AUTOSAR XML (schema 4-1-3)
standard types defined: boolean, sint8, uint16, uint32, uint8, boolean_CompuMethod, boolean_DataConstr, sint8_DataConstr, uint16_DataConstr, uint32_DataConstr, uint8_DataConstr, float32, Float
package /MICROSAR/Dem_swc/DataTypes
  5 x impl type:
    Dem_DebounceResetStatusType: compu {0=DEM_DEBOUNCE_STATUS_FREEZE, 1=DEM_DEBOUNCE_STATUS_RESET}, range raw 0..255, implementation-data-type=ImplementationDataTypes/uint8
    Dem_DTCFormatType: compu {0=DEM_DTC_FORMAT_OBD, 1=DEM_DTC_FORMAT_UDS, 2=DEM_DTC_FORMAT_J1939}, range raw 0..255, implementation-data-type=ImplementationDataTypes/uint8
    Dem_EventStatusType:
      compu {0=DEM_EVENT_STATUS_PASSED, 1=DEM_EVENT_STATUS_FAILED, 2=DEM_EVENT_STATUS_PREPASSED, 3=DEM_EVENT_STATUS_PREFAILED, 4=DEM_EVENT_STATUS_FDC_THRESHOLD_REACHED, 5=DEM_EVENT_STATUS_PASSED_CONDITIONS_NOT_FULFILLED, 6=DEM_EVENT_STATUS_FAILED_CONDITIONS_NOT_FULFILLED, 7=DEM_EVENT_STATUS_PREPASSED_CONDITIONS_NOT_FULFILLED, 8=DEM_EVENT_STATUS_PREFAILED_CONDITIONS_NOT_FULFILLED}
      range raw 0..255
      implementation-data-type=ImplementationDataTypes/uint8
    Dem_MaxDataValueType: category=ARRAY, sw-calibration-access=READ-ONLY
      element Dem_MaxDataValueTypeElement: array-size=4, array-size-semantics=FIXED-SIZE, implementation-data-type=ImplementationDataTypes/uint8
    Dem_UdsStatusByteType:
      compu {mask 1: 1=DEM_UDS_STATUS_TF (bit 0: TestFailed), mask 2: 2=DEM_UDS_STATUS_TFTOC (bit 1: TestFailedThisOperationCycle), mask 4: 4=DEM_UDS_STATUS_PDTC (bit 2: PendingDTC), mask 8: 8=DEM_UDS_STATUS_CDTC (bit 3: ConfirmedDTC), mask 16: 16=DEM_UDS_STATUS_TNCSLC (bit 4: TestNotCompletedSinceLastClear), mask 32: 32=DEM_UDS_STATUS_TFSLC (bit 5: TestFailedSinceLastClear), mask 64: 64=DEM_UDS_STATUS_TNCTOC (bit 6: TestNotCompletedThisOperationCycle), mask 128: 128=DEM_UDS_STATUS_WIR (bit 7: WarningIndicatorRequested)}
      range raw 0..255
      implementation-data-type=ImplementationDataTypes/uint8
package /MICROSAR/Dem_swc/Interfaces
  client server interface DiagnosticMonitor: is-service=true, service-kind=DIAGNOSTIC-EVENT-MANAGER
    11 x operation:
      GetDTCOfEvent: possible-error=[DEM_E_NO_DTC_AVAILABLE, E_NOT_OK]
        arg DTCFormat: type=Dem_DTCFormatType, direction=IN, server-argument-impl-policy=USE-ARGUMENT-TYPE
        arg DTCOfEvent: type=ImplementationDataTypes/uint32, direction=OUT, server-argument-impl-policy=USE-ARGUMENT-TYPE
      GetEventExtendedDataRecordEx: possible-error=[DEM_BUFFER_TOO_SMALL, DEM_NO_SUCH_ELEMENT, E_NOT_OK]
        arg RecordNumber: type=ImplementationDataTypes/uint8, direction=IN, server-argument-impl-policy=USE-ARGUMENT-TYPE
        arg DestBuffer: type=Dem_MaxDataValueType, direction=OUT, server-argument-impl-policy=USE-ARGUMENT-TYPE
        arg BufSize: type=ImplementationDataTypes/uint16, direction=INOUT, server-argument-impl-policy=USE-ARGUMENT-TYPE
      GetEventFailed: possible-error=E_NOT_OK
        arg EventFailed: type=ImplementationDataTypes/boolean, direction=OUT, server-argument-impl-policy=USE-ARGUMENT-TYPE
      GetEventFreezeFrameDataEx: possible-error=[DEM_BUFFER_TOO_SMALL, DEM_NO_SUCH_ELEMENT, E_NOT_OK]
        4 x arg, all with server-argument-impl-policy=USE-ARGUMENT-TYPE:
          RecordNumber: type=ImplementationDataTypes/uint8, direction=IN
          DataId: type=ImplementationDataTypes/uint16, direction=IN
          DestBuffer: type=Dem_MaxDataValueType, direction=OUT
          BufSize: type=ImplementationDataTypes/uint16, direction=INOUT
      GetEventStatus: possible-error=E_NOT_OK
        arg UDSStatusByte: type=Dem_UdsStatusByteType, direction=OUT, server-argument-impl-policy=USE-ARGUMENT-TYPE
      GetEventTested: possible-error=E_NOT_OK
        arg EventTested: type=ImplementationDataTypes/boolean, direction=OUT, server-argument-impl-policy=USE-ARGUMENT-TYPE
      GetEventUdsStatus: possible-error=E_NOT_OK
        arg UDSStatusByte: type=Dem_UdsStatusByteType, direction=OUT, server-argument-impl-policy=USE-ARGUMENT-TYPE
      GetFaultDetectionCounter: possible-error=[DEM_E_NO_FDC_AVAILABLE, E_NOT_OK]
        arg FaultDetectionCounter: type=sint8, direction=OUT, server-argument-impl-policy=USE-ARGUMENT-TYPE
      ResetEventDebounceStatus: possible-error=E_NOT_OK
        arg DebounceResetStatus: type=Dem_DebounceResetStatusType, direction=IN, server-argument-impl-policy=USE-ARGUMENT-TYPE
      ResetEventStatus: possible-error=E_NOT_OK
      SetEventStatus: possible-error=E_NOT_OK
        arg EventStatus: type=Dem_EventStatusType, direction=IN, server-argument-impl-policy=USE-ARGUMENT-TYPE
    5 x error:
      DEM_BUFFER_TOO_SMALL: error-code=21
      DEM_E_NO_DTC_AVAILABLE: error-code=10
      DEM_E_NO_FDC_AVAILABLE: error-code=14
      DEM_NO_SUCH_ELEMENT: error-code=48
      E_NOT_OK: error-code=1
package /UAES/ASW/CompuMethods
  compu method CM_boolean: 0=FALSE, 1=TRUE
package /UAES/ASW/DataConstrs
  range DC_boolean: raw 0..1
  range DC_Float: raw -INF..INF
  range DC_uint16: raw 0..65535
  range DC_uint32: raw 0..4294967295
  range DC_uint8: raw 0..255
package /UAES/ASW/DataTypeMappingSets
  data type mapping set DTMS_LOC_10ms
  data type mapping set DTMS_Lock_Ctrl
package /UAES/ASW/ImplementationDataTypes/Ground
  9 x constant specification:
    Cal_bPowerFillerOverride: value-spec=Cal_bPowerFillerOverride:0
    Cal_FillerCapResetVolt: value-spec=Cal_FillerCapResetVolt:2.6500000953674316
    Cal_MaxOperationTime: value-spec=Cal_MaxOperationTime:1000
    Cal_MaxStallPrm: value-spec=Cal_MaxStallPrm:10
    Cal_MaxStallTime: value-spec=Cal_MaxStallTime:50
    Cal_MaxStallVolt: value-spec=Cal_MaxStallVolt:4
    Cal_MinStallVolt: value-spec=Cal_MinStallVolt:2.5
    Cal_ReactWaitTime: value-spec=Cal_ReactWaitTime:50
    Cal_UinitDelay: value-spec=20
package /UAES/ASW/PortInterfaces
  164 x sender receiver interface:
    gASI_bPowerOnReset: invalidation-policy{data-element=gASI_bPowerOnReset/Val, handle-invalid=DONT-INVALIDATE}
      data Val: sw-calibration-access=READ-ONLY, type=ImplementationDataTypes/boolean
    gCAN_bBCS_VehSpdVD: invalidation-policy{data-element=gCAN_bBCS_VehSpdVD/Val, handle-invalid=DONT-INVALIDATE}
      data Val: sw-calibration-access=READ-ONLY, type=ImplementationDataTypes/boolean
    gCAN_bLCK_FillerCapLock_Alock: invalidation-policy{data-element=gCAN_bLCK_FillerCapLock_Alock/Val, handle-invalid=DONT-INVALIDATE}
      data Val: sw-calibration-access=READ-ONLY, type=ImplementationDataTypes/boolean
    gCAN_bLCK_FillerCapLock_Block: invalidation-policy{data-element=gCAN_bLCK_FillerCapLock_Block/Val, handle-invalid=DONT-INVALIDATE}
      data Val: sw-calibration-access=READ-ONLY, type=ImplementationDataTypes/boolean
    gCAN_bLCK_PowerFillerCap: invalidation-policy{data-element=gCAN_bLCK_PowerFillerCap/Val, handle-invalid=DONT-INVALIDATE}
      data Val: sw-calibration-access=READ-ONLY, type=ImplementationDataTypes/boolean
    gCAN_bLCK_RearLeftChildSaftyLock: invalidation-policy{data-element=gCAN_bLCK_RearLeftChildSaftyLock/Val, handle-invalid=DONT-INVALIDATE}
      data Val: sw-calibration-access=READ-ONLY, type=ImplementationDataTypes/boolean
    gCAN_bLCK_RearLeftDoorLock: invalidation-policy{data-element=gCAN_bLCK_RearLeftDoorLock/Val, handle-invalid=DONT-INVALIDATE}
      data Val: sw-calibration-access=READ-ONLY, type=ImplementationDataTypes/boolean
    gCAN_bLCK_RearLeftPowerDoor: invalidation-policy{data-element=gCAN_bLCK_RearLeftPowerDoor/Val, handle-invalid=DONT-INVALIDATE}
      data Val: sw-calibration-access=READ-ONLY, type=ImplementationDataTypes/boolean
    gCAN_bLCK_RearRightChildSaftyLock: invalidation-policy{data-element=gCAN_bLCK_RearRightChildSaftyLock/Val, handle-invalid=DONT-INVALIDATE}
      data Val: sw-calibration-access=READ-ONLY, type=ImplementationDataTypes/boolean
    gCAN_bLCK_RearRightDoorLock: invalidation-policy{data-element=gCAN_bLCK_RearRightDoorLock/Val, handle-invalid=DONT-INVALIDATE}
      data Val: sw-calibration-access=READ-ONLY, type=ImplementationDataTypes/boolean
    gCAN_bLCK_RearRightPowerDoor: invalidation-policy{data-element=gCAN_bLCK_RearRightPowerDoor/Val, handle-invalid=DONT-INVALIDATE}
      data Val: sw-calibration-access=READ-ONLY, type=ImplementationDataTypes/boolean
    gCAN_bLCK_TrunkLock: invalidation-policy{data-element=gCAN_bLCK_TrunkLock/Val, handle-invalid=DONT-INVALIDATE}
      data Val: sw-calibration-access=READ-ONLY, type=ImplementationDataTypes/boolean
    gCAN_u16BCS_VehSpd: invalidation-policy{data-element=gCAN_u16BCS_VehSpd/Val, handle-invalid=DONT-INVALIDATE}
      data Val: sw-calibration-access=READ-ONLY, type=ImplementationDataTypes/uint16
    gCAN_u8LCK_FillerCapCommandActionType: invalidation-policy{data-element=gCAN_u8LCK_FillerCapCommandActionType/Val, handle-invalid=DONT-INVALIDATE}
      data Val: sw-calibration-access=READ-ONLY, type=ImplementationDataTypes/uint8
    gCAN_u8LCK_LockCommandActionType: invalidation-policy{data-element=gCAN_u8LCK_LockCommandActionType/Val, handle-invalid=DONT-INVALIDATE}
      data Val: sw-calibration-access=READ-ONLY, type=ImplementationDataTypes/uint8
    gCAN_u8LCK_PowerDoorCommandActionType: invalidation-policy{data-element=gCAN_u8LCK_PowerDoorCommandActionType/Val, handle-invalid=DONT-INVALIDATE}
      data Val: sw-calibration-access=READ-ONLY, type=ImplementationDataTypes/uint8
    gCAN_u8SRS_CrashOutputSt: invalidation-policy{data-element=gCAN_u8SRS_CrashOutputSt/Val, handle-invalid=DONT-INVALIDATE}
      data Val: sw-calibration-access=READ-ONLY, type=ImplementationDataTypes/uint8
    gCAN_u8UMM_UsageModeSt: invalidation-policy{data-element=gCAN_u8UMM_UsageModeSt/Val, handle-invalid=DONT-INVALIDATE}
      data Val: sw-calibration-access=READ-ONLY, type=ImplementationDataTypes/uint8
    gCAN_u8VCU_CrntGearLvl_A02: invalidation-policy{data-element=gCAN_u8VCU_CrntGearLvl_A02/Val, handle-invalid=DONT-INVALIDATE}
      data Val: sw-calibration-access=READ-ONLY, type=ImplementationDataTypes/uint8
    gCAN_u8VCU_CrntGearLvl_A09: invalidation-policy{data-element=gCAN_u8VCU_CrntGearLvl_A09/Val, handle-invalid=DONT-INVALIDATE}
      data Val: sw-calibration-access=READ-ONLY, type=ImplementationDataTypes/uint8
    gCFG_bLCK_PowerFillerCapCfg: invalidation-policy{data-element=gCFG_bLCK_PowerFillerCapCfg/Val, handle-invalid=DONT-INVALIDATE}
      data Val: sw-calibration-access=READ-ONLY, type=ImplementationDataTypes/boolean
    gCrash_bRLCrashUnlockSwt: invalidation-policy{data-element=gCrash_bRLCrashUnlockSwt/Val, handle-invalid=DONT-INVALIDATE}
      data Val: sw-calibration-access=READ-ONLY, type=ImplementationDataTypes/boolean
    gCrash_bRRCrashUnlockSwt: invalidation-policy{data-element=gCrash_bRRCrashUnlockSwt/Val, handle-invalid=DONT-INVALIDATE}
      data Val: sw-calibration-access=READ-ONLY, type=ImplementationDataTypes/boolean
    gDoor_bChrgCapAjarSt: invalidation-policy{data-element=gDoor_bChrgCapAjarSt/Val, handle-invalid=DONT-INVALIDATE}
      data Val: sw-calibration-access=READ-ONLY, type=ImplementationDataTypes/boolean
    gDoor_bFuelFlapAjarSt: invalidation-policy{data-element=gDoor_bFuelFlapAjarSt/Val, handle-invalid=DONT-INVALIDATE}
      data Val: sw-calibration-access=READ-ONLY, type=ImplementationDataTypes/boolean
    gDoor_bRLDoorAjarSt: invalidation-policy{data-element=gDoor_bRLDoorAjarSt/Val, handle-invalid=DONT-INVALIDATE}
      data Val: sw-calibration-access=READ-ONLY, type=ImplementationDataTypes/boolean
    gDoor_bRRDoorAjarSt: invalidation-policy{data-element=gDoor_bRRDoorAjarSt/Val, handle-invalid=DONT-INVALIDATE}
      data Val: sw-calibration-access=READ-ONLY, type=ImplementationDataTypes/boolean
    gDoor_bTrunkAjarSt: invalidation-policy{data-element=gDoor_bTrunkAjarSt/Val, handle-invalid=DONT-INVALIDATE}
      data Val: sw-calibration-access=READ-ONLY, type=ImplementationDataTypes/boolean
    gLOC_bLCK_ExterSwOpenFillerCapReq: invalidation-policy{data-element=gLOC_bLCK_ExterSwOpenFillerCapReq/Val, handle-invalid=DONT-INVALIDATE}
      data Val: sw-calibration-access=READ-ONLY, type=ImplementationDataTypes/boolean
    gLOC_bLCK_RearLeftChildSaftyLockSt: invalidation-policy{data-element=gLOC_bLCK_RearLeftChildSaftyLockSt/Val, handle-invalid=DONT-INVALIDATE}
      data Val: sw-calibration-access=READ-ONLY, type=ImplementationDataTypes/boolean
    gLOC_bLCK_RearLeftDoorAjarSt: invalidation-policy{data-element=gLOC_bLCK_RearLeftDoorAjarSt/Val, handle-invalid=DONT-INVALIDATE}
      data Val: sw-calibration-access=READ-ONLY, type=ImplementationDataTypes/boolean
    gLOC_bLCK_RearLeftDoorLockSt: invalidation-policy{data-element=gLOC_bLCK_RearLeftDoorLockSt/Val, handle-invalid=DONT-INVALIDATE}
      data Val: sw-calibration-access=READ-ONLY, type=ImplementationDataTypes/boolean
    gLOC_bLCK_RearLeftDoorOpenSt: invalidation-policy{data-element=gLOC_bLCK_RearLeftDoorOpenSt/Val, handle-invalid=DONT-INVALIDATE}
      data Val: sw-calibration-access=READ-ONLY, type=ImplementationDataTypes/boolean
    gLOC_bLCK_RearRightChildSaftyLockSt: invalidation-policy{data-element=gLOC_bLCK_RearRightChildSaftyLockSt/Val, handle-invalid=DONT-INVALIDATE}
      data Val: sw-calibration-access=READ-ONLY, type=ImplementationDataTypes/boolean
    gLOC_bLCK_RearRightDoorAjarSt: invalidation-policy{data-element=gLOC_bLCK_RearRightDoorAjarSt/Val, handle-invalid=DONT-INVALIDATE}
      data Val: sw-calibration-access=READ-ONLY, type=ImplementationDataTypes/boolean
    gLOC_bLCK_RearRightDoorLockSt: invalidation-policy{data-element=gLOC_bLCK_RearRightDoorLockSt/Val, handle-invalid=DONT-INVALIDATE}
      data Val: sw-calibration-access=READ-ONLY, type=ImplementationDataTypes/boolean
    gLOC_bLCK_RearRightDoorOpenSt: invalidation-policy{data-element=gLOC_bLCK_RearRightDoorOpenSt/Val, handle-invalid=DONT-INVALIDATE}
      data Val: sw-calibration-access=READ-ONLY, type=ImplementationDataTypes/boolean
    gLOC_bLCK_TrunkAjarSt: invalidation-policy{data-element=gLOC_bLCK_TrunkAjarSt/Val, handle-invalid=DONT-INVALIDATE}
      data Val: sw-calibration-access=READ-ONLY, type=ImplementationDataTypes/boolean
    gLOC_bUINM_RearLeftPowerReleaseReq: invalidation-policy{data-element=gLOC_bUINM_RearLeftPowerReleaseReq/Val, handle-invalid=DONT-INVALIDATE}
      data Val: sw-calibration-access=READ-ONLY, type=ImplementationDataTypes/boolean
    gLOC_bUINM_RearRightPowerReleaseReq: invalidation-policy{data-element=gLOC_bUINM_RearRightPowerReleaseReq/Val, handle-invalid=DONT-INVALIDATE}
      data Val: sw-calibration-access=READ-ONLY, type=ImplementationDataTypes/boolean
    gLOC_u32AllowSleep_Local: invalidation-policy{data-element=gLOC_u32AllowSleep_Local/Val, handle-invalid=DONT-INVALIDATE}
      data Val: sw-calibration-access=READ-ONLY, type=ImplementationDataTypes/uint32
    gLOC_u32AllowSleep_NW: invalidation-policy{data-element=gLOC_u32AllowSleep_NW/Val, handle-invalid=DONT-INVALIDATE}
      data Val: sw-calibration-access=READ-ONLY, type=ImplementationDataTypes/uint32
    gLOC_u8LCK_FillerCapAction: invalidation-policy{data-element=gLOC_u8LCK_FillerCapAction/Val, handle-invalid=DONT-INVALIDATE}
      data Val: sw-calibration-access=READ-ONLY, type=ImplementationDataTypes/uint8
    gLOC_u8LCK_FillerCapAngle: invalidation-policy{data-element=gLOC_u8LCK_FillerCapAngle/Val, handle-invalid=DONT-INVALIDATE}
      data Val: sw-calibration-access=READ-ONLY, type=ImplementationDataTypes/uint8
    gLOC_u8LCK_FillerCapLock_AAction: invalidation-policy{data-element=gLOC_u8LCK_FillerCapLock_AAction/Val, handle-invalid=DONT-INVALIDATE}
      data Val: sw-calibration-access=READ-ONLY, type=ImplementationDataTypes/uint8
    gLOC_u8LCK_FillerCapLock_BAction: invalidation-policy{data-element=gLOC_u8LCK_FillerCapLock_BAction/Val, handle-invalid=DONT-INVALIDATE}
      data Val: sw-calibration-access=READ-ONLY, type=ImplementationDataTypes/uint8
    gLOC_u8LCK_RearLeftChildSaftyLockAction: invalidation-policy{data-element=gLOC_u8LCK_RearLeftChildSaftyLockAction/Val, handle-invalid=DONT-INVALIDATE}
      data Val: sw-calibration-access=READ-ONLY, type=ImplementationDataTypes/uint8
    gLOC_u8LCK_RearLeftDoorLockAction: invalidation-policy{data-element=gLOC_u8LCK_RearLeftDoorLockAction/Val, handle-invalid=DONT-INVALIDATE}
      data Val: sw-calibration-access=READ-ONLY, type=ImplementationDataTypes/uint8
    gLOC_u8LCK_RearLeftPowerDoorAction: invalidation-policy{data-element=gLOC_u8LCK_RearLeftPowerDoorAction/Val, handle-invalid=DONT-INVALIDATE}
      data Val: sw-calibration-access=READ-ONLY, type=ImplementationDataTypes/uint8
    gLOC_u8LCK_RearRightChildSaftyLockAction: invalidation-policy{data-element=gLOC_u8LCK_RearRightChildSaftyLockAction/Val, handle-invalid=DONT-INVALIDATE}
      data Val: sw-calibration-access=READ-ONLY, type=ImplementationDataTypes/uint8
    gLOC_u8LCK_RearRightDoorLockAction: invalidation-policy{data-element=gLOC_u8LCK_RearRightDoorLockAction/Val, handle-invalid=DONT-INVALIDATE}
      data Val: sw-calibration-access=READ-ONLY, type=ImplementationDataTypes/uint8
    gLOC_u8LCK_RearRightPowerDoorAction: invalidation-policy{data-element=gLOC_u8LCK_RearRightPowerDoorAction/Val, handle-invalid=DONT-INVALIDATE}
      data Val: sw-calibration-access=READ-ONLY, type=ImplementationDataTypes/uint8
    gLOC_u8LCK_TrunkLockAction: invalidation-policy{data-element=gLOC_u8LCK_TrunkLockAction/Val, handle-invalid=DONT-INVALIDATE}
      data Val: sw-calibration-access=READ-ONLY, type=ImplementationDataTypes/uint8
    gLock_bChrgCapSwt: invalidation-policy{data-element=gLock_bChrgCapSwt/Val, handle-invalid=DONT-INVALIDATE}
      data Val: sw-calibration-access=READ-ONLY, type=ImplementationDataTypes/boolean
    gLock_bLCK_FillerCapASt: invalidation-policy{data-element=gLock_bLCK_FillerCapASt/Val, handle-invalid=DONT-INVALIDATE}
      data Val: sw-calibration-access=READ-ONLY, type=ImplementationDataTypes/boolean
    gLock_bLCK_FillerCapBSt: invalidation-policy{data-element=gLock_bLCK_FillerCapBSt/Val, handle-invalid=DONT-INVALIDATE}
      data Val: sw-calibration-access=READ-ONLY, type=ImplementationDataTypes/boolean
    gLock_bLCK_RearLeftPowerReleaseFailedRemind: invalidation-policy{data-element=gLock_bLCK_RearLeftPowerReleaseFailedRemind/Val, handle-invalid=DONT-INVALIDATE}
      data Val: sw-calibration-access=READ-ONLY, type=ImplementationDataTypes/boolean
    gLock_bLCK_RearRightPowerReleaseFailedRemind: invalidation-policy{data-element=gLock_bLCK_RearRightPowerReleaseFailedRemind/Val, handle-invalid=DONT-INVALIDATE}
      data Val: sw-calibration-access=READ-ONLY, type=ImplementationDataTypes/boolean
    gLock_bRLChildLockFbSt: invalidation-policy{data-element=gLock_bRLChildLockFbSt/Val, handle-invalid=DONT-INVALIDATE}
      data Val: sw-calibration-access=READ-ONLY, type=ImplementationDataTypes/boolean
    gLock_bRLChildLockMotorTrigUds: invalidation-policy{data-element=gLock_bRLChildLockMotorTrigUds/Val, handle-invalid=DONT-INVALIDATE}
      data Val: sw-calibration-access=READ-ONLY, type=ImplementationDataTypes/boolean
    gLock_bRLDoorLockFbSt: invalidation-policy{data-element=gLock_bRLDoorLockFbSt/Val, handle-invalid=DONT-INVALIDATE}
      data Val: sw-calibration-access=READ-ONLY, type=ImplementationDataTypes/boolean
    gLock_bRLDoorLockMotorTrigUds: invalidation-policy{data-element=gLock_bRLDoorLockMotorTrigUds/Val, handle-invalid=DONT-INVALIDATE}
      data Val: sw-calibration-access=READ-ONLY, type=ImplementationDataTypes/boolean
    gLock_bRLPwrDoorTrigUds: invalidation-policy{data-element=gLock_bRLPwrDoorTrigUds/Val, handle-invalid=DONT-INVALIDATE}
      data Val: sw-calibration-access=READ-ONLY, type=ImplementationDataTypes/boolean
    gLock_bRRChildLockFbSt: invalidation-policy{data-element=gLock_bRRChildLockFbSt/Val, handle-invalid=DONT-INVALIDATE}
      data Val: sw-calibration-access=READ-ONLY, type=ImplementationDataTypes/boolean
    gLock_bRRChildLockMotorTrigUds: invalidation-policy{data-element=gLock_bRRChildLockMotorTrigUds/Val, handle-invalid=DONT-INVALIDATE}
      data Val: sw-calibration-access=READ-ONLY, type=ImplementationDataTypes/boolean
    gLock_bRRDoorLockFbSt: invalidation-policy{data-element=gLock_bRRDoorLockFbSt/Val, handle-invalid=DONT-INVALIDATE}
      data Val: sw-calibration-access=READ-ONLY, type=ImplementationDataTypes/boolean
    gLock_bRRDoorLockMotorTrigUds: invalidation-policy{data-element=gLock_bRRDoorLockMotorTrigUds/Val, handle-invalid=DONT-INVALIDATE}
      data Val: sw-calibration-access=READ-ONLY, type=ImplementationDataTypes/boolean
    gLock_bRRPwrDoorTrigUds: invalidation-policy{data-element=gLock_bRRPwrDoorTrigUds/Val, handle-invalid=DONT-INVALIDATE}
      data Val: sw-calibration-access=READ-ONLY, type=ImplementationDataTypes/boolean
    gLock_bUINM_RearLeftPowerReleaseFaultSt: invalidation-policy{data-element=gLock_bUINM_RearLeftPowerReleaseFaultSt/Val, handle-invalid=DONT-INVALIDATE}
      data Val: sw-calibration-access=READ-ONLY, type=ImplementationDataTypes/boolean
    gLock_bUINM_RearRightPowerReleaseFaultSt: invalidation-policy{data-element=gLock_bUINM_RearRightPowerReleaseFaultSt/Val, handle-invalid=DONT-INVALIDATE}
      data Val: sw-calibration-access=READ-ONLY, type=ImplementationDataTypes/boolean
    gLock_u16ChrgCapPosVolt: invalidation-policy{data-element=gLock_u16ChrgCapPosVolt/Val, handle-invalid=DONT-INVALIDATE}
      data Val: sw-calibration-access=READ-ONLY, type=ImplementationDataTypes/uint16
    gLock_u8BootLockMotorPs: invalidation-policy{data-element=gLock_u8BootLockMotorPs/Val, handle-invalid=DONT-INVALIDATE}
      data Val: sw-calibration-access=READ-ONLY, type=ImplementationDataTypes/uint8
    gLock_u8ChrgCapLockMotorPs: invalidation-policy{data-element=gLock_u8ChrgCapLockMotorPs/Val, handle-invalid=DONT-INVALIDATE}
      data Val: sw-calibration-access=READ-ONLY, type=ImplementationDataTypes/uint8
    gLock_u8DiagEnbCnd: invalidation-policy{data-element=gLock_u8DiagEnbCnd/Val, handle-invalid=DONT-INVALIDATE}
      data Val: sw-calibration-access=READ-ONLY, type=ImplementationDataTypes/uint8
    gLock_u8OilTankLockMotorPs: invalidation-policy{data-element=gLock_u8OilTankLockMotorPs/Val, handle-invalid=DONT-INVALIDATE}
      data Val: sw-calibration-access=READ-ONLY, type=ImplementationDataTypes/uint8
    gLock_u8RLChildLockMotorPs: invalidation-policy{data-element=gLock_u8RLChildLockMotorPs/Val, handle-invalid=DONT-INVALIDATE}
      data Val: sw-calibration-access=READ-ONLY, type=ImplementationDataTypes/uint8
    gLock_u8RLChildLockMotorUds: invalidation-policy{data-element=gLock_u8RLChildLockMotorUds/Val, handle-invalid=DONT-INVALIDATE}
      data Val: sw-calibration-access=READ-ONLY, type=ImplementationDataTypes/uint8
    gLock_u8RLDoorLockMotorPs: invalidation-policy{data-element=gLock_u8RLDoorLockMotorPs/Val, handle-invalid=DONT-INVALIDATE}
      data Val: sw-calibration-access=READ-ONLY, type=ImplementationDataTypes/uint8
    gLock_u8RLDoorLockMotorUds: invalidation-policy{data-element=gLock_u8RLDoorLockMotorUds/Val, handle-invalid=DONT-INVALIDATE}
      data Val: sw-calibration-access=READ-ONLY, type=ImplementationDataTypes/uint8
    gLock_u8RLPwrDoorUds: invalidation-policy{data-element=gLock_u8RLPwrDoorUds/Val, handle-invalid=DONT-INVALIDATE}
      data Val: sw-calibration-access=READ-ONLY, type=ImplementationDataTypes/uint8
    gLock_u8RLPwrRelsMotorPs: invalidation-policy{data-element=gLock_u8RLPwrRelsMotorPs/Val, handle-invalid=DONT-INVALIDATE}
      data Val: sw-calibration-access=READ-ONLY, type=ImplementationDataTypes/uint8
    gLock_u8RRChildLockMotorPs: invalidation-policy{data-element=gLock_u8RRChildLockMotorPs/Val, handle-invalid=DONT-INVALIDATE}
      data Val: sw-calibration-access=READ-ONLY, type=ImplementationDataTypes/uint8
    gLock_u8RRChildLockMotorUds: invalidation-policy{data-element=gLock_u8RRChildLockMotorUds/Val, handle-invalid=DONT-INVALIDATE}
      data Val: sw-calibration-access=READ-ONLY, type=ImplementationDataTypes/uint8
    gLock_u8RRDoorLockMotorPs: invalidation-policy{data-element=gLock_u8RRDoorLockMotorPs/Val, handle-invalid=DONT-INVALIDATE}
      data Val: sw-calibration-access=READ-ONLY, type=ImplementationDataTypes/uint8
    gLock_u8RRDoorLockMotorUds: invalidation-policy{data-element=gLock_u8RRDoorLockMotorUds/Val, handle-invalid=DONT-INVALIDATE}
      data Val: sw-calibration-access=READ-ONLY, type=ImplementationDataTypes/uint8
    gLock_u8RRPwrDoorUds: invalidation-policy{data-element=gLock_u8RRPwrDoorUds/Val, handle-invalid=DONT-INVALIDATE}
      data Val: sw-calibration-access=READ-ONLY, type=ImplementationDataTypes/uint8
    gLock_u8RRPwrRelsMotorPs: invalidation-policy{data-element=gLock_u8RRPwrRelsMotorPs/Val, handle-invalid=DONT-INVALIDATE}
      data Val: sw-calibration-access=READ-ONLY, type=ImplementationDataTypes/uint8
    gLockCtrl_bChrgCapSwtDTCFlag: invalidation-policy{data-element=gLockCtrl_bChrgCapSwtDTCFlag/Val, handle-invalid=DONT-INVALIDATE}
      data Val: sw-calibration-access=READ-ONLY, type=ImplementationDataTypes/boolean
    gLockCtrl_bFillerCapAMotorMoveFlag: invalidation-policy{data-element=gLockCtrl_bFillerCapAMotorMoveFlag/Val, handle-invalid=DONT-INVALIDATE}
      data Val: sw-calibration-access=READ-ONLY, type=ImplementationDataTypes/boolean
    gLockCtrl_bFillerCapARelockFlag: invalidation-policy{data-element=gLockCtrl_bFillerCapARelockFlag/Val, handle-invalid=DONT-INVALIDATE}
      data Val: sw-calibration-access=READ-ONLY, type=ImplementationDataTypes/boolean
    gLockCtrl_bFillerCapAReUnlockFlag: invalidation-policy{data-element=gLockCtrl_bFillerCapAReUnlockFlag/Val, handle-invalid=DONT-INVALIDATE}
      data Val: sw-calibration-access=READ-ONLY, type=ImplementationDataTypes/boolean
    gLockCtrl_bFillerCapBMotorMoveFlag: invalidation-policy{data-element=gLockCtrl_bFillerCapBMotorMoveFlag/Val, handle-invalid=DONT-INVALIDATE}
      data Val: sw-calibration-access=READ-ONLY, type=ImplementationDataTypes/boolean
    gLockCtrl_bFillerCapBRelockFlag: invalidation-policy{data-element=gLockCtrl_bFillerCapBRelockFlag/Val, handle-invalid=DONT-INVALIDATE}
      data Val: sw-calibration-access=READ-ONLY, type=ImplementationDataTypes/boolean
    gLockCtrl_bFillerCapBReUnlockFlag: invalidation-policy{data-element=gLockCtrl_bFillerCapBReUnlockFlag/Val, handle-invalid=DONT-INVALIDATE}
      data Val: sw-calibration-access=READ-ONLY, type=ImplementationDataTypes/boolean
    gLockCtrl_bRLCSLDoorMotorMoveFlag: invalidation-policy{data-element=gLockCtrl_bRLCSLDoorMotorMoveFlag/Val, handle-invalid=DONT-INVALIDATE}
      data Val: sw-calibration-access=READ-ONLY, type=ImplementationDataTypes/boolean
    gLockCtrl_bRLCSLLockMotorReEmergencyunlockflag: invalidation-policy{data-element=gLockCtrl_bRLCSLLockMotorReEmergencyunlockflag/Val, handle-invalid=DONT-INVALIDATE}
      data Val: sw-calibration-access=READ-ONLY, type=ImplementationDataTypes/boolean
    gLockCtrl_bRLCSLLockMotorRelockflag: invalidation-policy{data-element=gLockCtrl_bRLCSLLockMotorRelockflag/Val, handle-invalid=DONT-INVALIDATE}
      data Val: sw-calibration-access=READ-ONLY, type=ImplementationDataTypes/boolean
    gLockCtrl_bRLCSLLockMotorReReverseunlockflag: invalidation-policy{data-element=gLockCtrl_bRLCSLLockMotorReReverseunlockflag/Val, handle-invalid=DONT-INVALIDATE}
      data Val: sw-calibration-access=READ-ONLY, type=ImplementationDataTypes/boolean
    gLockCtrl_bRLCSLLockMotorReunlockflag: invalidation-policy{data-element=gLockCtrl_bRLCSLLockMotorReunlockflag/Val, handle-invalid=DONT-INVALIDATE}
      data Val: sw-calibration-access=READ-ONLY, type=ImplementationDataTypes/boolean
    gLockCtrl_bRLDoorMotorMoveFlag: invalidation-policy{data-element=gLockCtrl_bRLDoorMotorMoveFlag/Val, handle-invalid=DONT-INVALIDATE}
      data Val: sw-calibration-access=READ-ONLY, type=ImplementationDataTypes/boolean
    gLockCtrl_bRLLockMotorReEmergencyunlockflag: invalidation-policy{data-element=gLockCtrl_bRLLockMotorReEmergencyunlockflag/Val, handle-invalid=DONT-INVALIDATE}
      data Val: sw-calibration-access=READ-ONLY, type=ImplementationDataTypes/boolean
    gLockCtrl_bRLLockMotorRelockflag: invalidation-policy{data-element=gLockCtrl_bRLLockMotorRelockflag/Val, handle-invalid=DONT-INVALIDATE}
      data Val: sw-calibration-access=READ-ONLY, type=ImplementationDataTypes/boolean
    gLockCtrl_bRLLockMotorReReverseunlockflag: invalidation-policy{data-element=gLockCtrl_bRLLockMotorReReverseunlockflag/Val, handle-invalid=DONT-INVALIDATE}
      data Val: sw-calibration-access=READ-ONLY, type=ImplementationDataTypes/boolean
    gLockCtrl_bRLLockMotorReunlockflag: invalidation-policy{data-element=gLockCtrl_bRLLockMotorReunlockflag/Val, handle-invalid=DONT-INVALIDATE}
      data Val: sw-calibration-access=READ-ONLY, type=ImplementationDataTypes/boolean
    gLockCtrl_bRLPowerDoorRelsMotorMoveFlag: invalidation-policy{data-element=gLockCtrl_bRLPowerDoorRelsMotorMoveFlag/Val, handle-invalid=DONT-INVALIDATE}
      data Val: sw-calibration-access=READ-ONLY, type=ImplementationDataTypes/boolean
    gLockCtrl_bRLPowerDoorReReleaseflag: invalidation-policy{data-element=gLockCtrl_bRLPowerDoorReReleaseflag/Val, handle-invalid=DONT-INVALIDATE}
      data Val: sw-calibration-access=READ-ONLY, type=ImplementationDataTypes/boolean
    gLockCtrl_bRLPowerReleaseSwDTCFlag: invalidation-policy{data-element=gLockCtrl_bRLPowerReleaseSwDTCFlag/Val, handle-invalid=DONT-INVALIDATE}
      data Val: sw-calibration-access=READ-ONLY, type=ImplementationDataTypes/boolean
    gLockCtrl_bRRCSLDoorMotorMoveFlag: invalidation-policy{data-element=gLockCtrl_bRRCSLDoorMotorMoveFlag/Val, handle-invalid=DONT-INVALIDATE}
      data Val: sw-calibration-access=READ-ONLY, type=ImplementationDataTypes/boolean
    gLockCtrl_bRRCSLLockMotorReEmergencyunlockflag: invalidation-policy{data-element=gLockCtrl_bRRCSLLockMotorReEmergencyunlockflag/Val, handle-invalid=DONT-INVALIDATE}
      data Val: sw-calibration-access=READ-ONLY, type=ImplementationDataTypes/boolean
    gLockCtrl_bRRCSLLockMotorRelockflag: invalidation-policy{data-element=gLockCtrl_bRRCSLLockMotorRelockflag/Val, handle-invalid=DONT-INVALIDATE}
      data Val: sw-calibration-access=READ-ONLY, type=ImplementationDataTypes/boolean
    gLockCtrl_bRRCSLLockMotorReReverseunlockflag: invalidation-policy{data-element=gLockCtrl_bRRCSLLockMotorReReverseunlockflag/Val, handle-invalid=DONT-INVALIDATE}
      data Val: sw-calibration-access=READ-ONLY, type=ImplementationDataTypes/boolean
    gLockCtrl_bRRCSLLockMotorReunlockflag: invalidation-policy{data-element=gLockCtrl_bRRCSLLockMotorReunlockflag/Val, handle-invalid=DONT-INVALIDATE}
      data Val: sw-calibration-access=READ-ONLY, type=ImplementationDataTypes/boolean
    gLockCtrl_bRRDoorMotorMoveFlag: invalidation-policy{data-element=gLockCtrl_bRRDoorMotorMoveFlag/Val, handle-invalid=DONT-INVALIDATE}
      data Val: sw-calibration-access=READ-ONLY, type=ImplementationDataTypes/boolean
    gLockCtrl_bRRLockMotorReEmergencyunlockflag: invalidation-policy{data-element=gLockCtrl_bRRLockMotorReEmergencyunlockflag/Val, handle-invalid=DONT-INVALIDATE}
      data Val: sw-calibration-access=READ-ONLY, type=ImplementationDataTypes/boolean
    gLockCtrl_bRRLockMotorRelockflag: invalidation-policy{data-element=gLockCtrl_bRRLockMotorRelockflag/Val, handle-invalid=DONT-INVALIDATE}
      data Val: sw-calibration-access=READ-ONLY, type=ImplementationDataTypes/boolean
    gLockCtrl_bRRLockMotorReReverseunlockflag: invalidation-policy{data-element=gLockCtrl_bRRLockMotorReReverseunlockflag/Val, handle-invalid=DONT-INVALIDATE}
      data Val: sw-calibration-access=READ-ONLY, type=ImplementationDataTypes/boolean
    gLockCtrl_bRRLockMotorReunlockflag: invalidation-policy{data-element=gLockCtrl_bRRLockMotorReunlockflag/Val, handle-invalid=DONT-INVALIDATE}
      data Val: sw-calibration-access=READ-ONLY, type=ImplementationDataTypes/boolean
    gLockCtrl_bRRPowerDoorRelsMotorMoveFlag: invalidation-policy{data-element=gLockCtrl_bRRPowerDoorRelsMotorMoveFlag/Val, handle-invalid=DONT-INVALIDATE}
      data Val: sw-calibration-access=READ-ONLY, type=ImplementationDataTypes/boolean
    gLockCtrl_bRRPowerDoorReReleaseflag: invalidation-policy{data-element=gLockCtrl_bRRPowerDoorReReleaseflag/Val, handle-invalid=DONT-INVALIDATE}
      data Val: sw-calibration-access=READ-ONLY, type=ImplementationDataTypes/boolean
    gLockCtrl_bRRPowerReleaseSwDTCFlag: invalidation-policy{data-element=gLockCtrl_bRRPowerReleaseSwDTCFlag/Val, handle-invalid=DONT-INVALIDATE}
      data Val: sw-calibration-access=READ-ONLY, type=ImplementationDataTypes/boolean
    gLockCtrl_bTrunkMotorMoveFlag: invalidation-policy{data-element=gLockCtrl_bTrunkMotorMoveFlag/Val, handle-invalid=DONT-INVALIDATE}
      data Val: sw-calibration-access=READ-ONLY, type=ImplementationDataTypes/boolean
    gLockCtrl_bTrunkReUnlockFlag: invalidation-policy{data-element=gLockCtrl_bTrunkReUnlockFlag/Val, handle-invalid=DONT-INVALIDATE}
      data Val: sw-calibration-access=READ-ONLY, type=ImplementationDataTypes/boolean
    gLockCtrl_u8BootLockMotorOutput: invalidation-policy{data-element=gLockCtrl_u8BootLockMotorOutput/Val, handle-invalid=DONT-INVALIDATE}
      data Val: sw-calibration-access=READ-ONLY, type=ImplementationDataTypes/uint8
    gLockCtrl_u8ChrgCapLockMotorOutput: invalidation-policy{data-element=gLockCtrl_u8ChrgCapLockMotorOutput/Val, handle-invalid=DONT-INVALIDATE}
      data Val: sw-calibration-access=READ-ONLY, type=ImplementationDataTypes/uint8
    gLockCtrl_u8FillerCapAMotorCmd: invalidation-policy{data-element=gLockCtrl_u8FillerCapAMotorCmd/Val, handle-invalid=DONT-INVALIDATE}
      data Val: sw-calibration-access=READ-ONLY, type=ImplementationDataTypes/uint8
    gLockCtrl_u8FillerCapBMotorCmd: invalidation-policy{data-element=gLockCtrl_u8FillerCapBMotorCmd/Val, handle-invalid=DONT-INVALIDATE}
      data Val: sw-calibration-access=READ-ONLY, type=ImplementationDataTypes/uint8
    gLockCtrl_u8FillerCapLockReqA: invalidation-policy{data-element=gLockCtrl_u8FillerCapLockReqA/Val, handle-invalid=DONT-INVALIDATE}
      data Val: sw-calibration-access=READ-ONLY, type=ImplementationDataTypes/uint8
    gLockCtrl_u8FillerCapLockReqB: invalidation-policy{data-element=gLockCtrl_u8FillerCapLockReqB/Val, handle-invalid=DONT-INVALIDATE}
      data Val: sw-calibration-access=READ-ONLY, type=ImplementationDataTypes/uint8
    gLockCtrl_u8OilTankLockMotorOutput: invalidation-policy{data-element=gLockCtrl_u8OilTankLockMotorOutput/Val, handle-invalid=DONT-INVALIDATE}
      data Val: sw-calibration-access=READ-ONLY, type=ImplementationDataTypes/uint8
    gLockCtrl_u8RLChildLockMotorOutput: invalidation-policy{data-element=gLockCtrl_u8RLChildLockMotorOutput/Val, handle-invalid=DONT-INVALIDATE}
      data Val: sw-calibration-access=READ-ONLY, type=ImplementationDataTypes/uint8
    gLockCtrl_u8RLCSLLockMotorCmd: invalidation-policy{data-element=gLockCtrl_u8RLCSLLockMotorCmd/Val, handle-invalid=DONT-INVALIDATE}
      data Val: sw-calibration-access=READ-ONLY, type=ImplementationDataTypes/uint8
    gLockCtrl_u8RLDoorElecRelMotorOutput: invalidation-policy{data-element=gLockCtrl_u8RLDoorElecRelMotorOutput/Val, handle-invalid=DONT-INVALIDATE}
      data Val: sw-calibration-access=READ-ONLY, type=ImplementationDataTypes/uint8
    gLockCtrl_u8RLDoorElecRelPWMMotorOutput: invalidation-policy{data-element=gLockCtrl_u8RLDoorElecRelPWMMotorOutput/Val, handle-invalid=DONT-INVALIDATE}
      data Val: sw-calibration-access=READ-ONLY, type=ImplementationDataTypes/uint8
    gLockCtrl_u8RLDoorLockMotorOutput: invalidation-policy{data-element=gLockCtrl_u8RLDoorLockMotorOutput/Val, handle-invalid=DONT-INVALIDATE}
      data Val: sw-calibration-access=READ-ONLY, type=ImplementationDataTypes/uint8
    gLockCtrl_u8RLLockMotorCmd: invalidation-policy{data-element=gLockCtrl_u8RLLockMotorCmd/Val, handle-invalid=DONT-INVALIDATE}
      data Val: sw-calibration-access=READ-ONLY, type=ImplementationDataTypes/uint8
    gLockCtrl_u8RLPowerDoorRelCmd: invalidation-policy{data-element=gLockCtrl_u8RLPowerDoorRelCmd/Val, handle-invalid=DONT-INVALIDATE}
      data Val: sw-calibration-access=READ-ONLY, type=ImplementationDataTypes/uint8
    gLockCtrl_u8RLPowerDoorRelDoneFlag: invalidation-policy{data-element=gLockCtrl_u8RLPowerDoorRelDoneFlag/Val, handle-invalid=DONT-INVALIDATE}
      data Val: sw-calibration-access=READ-ONLY, type=ImplementationDataTypes/uint8
    gLockCtrl_u8RLPowerDoorReq: invalidation-policy{data-element=gLockCtrl_u8RLPowerDoorReq/Val, handle-invalid=DONT-INVALIDATE}
      data Val: sw-calibration-access=READ-ONLY, type=ImplementationDataTypes/uint8
    gLockCtrl_u8RRChildLockMotorOutput: invalidation-policy{data-element=gLockCtrl_u8RRChildLockMotorOutput/Val, handle-invalid=DONT-INVALIDATE}
      data Val: sw-calibration-access=READ-ONLY, type=ImplementationDataTypes/uint8
    gLockCtrl_u8RRCSLLockMotorCmd: invalidation-policy{data-element=gLockCtrl_u8RRCSLLockMotorCmd/Val, handle-invalid=DONT-INVALIDATE}
      data Val: sw-calibration-access=READ-ONLY, type=ImplementationDataTypes/uint8
    gLockCtrl_u8RRDoorElecRelMotorOutput: invalidation-policy{data-element=gLockCtrl_u8RRDoorElecRelMotorOutput/Val, handle-invalid=DONT-INVALIDATE}
      data Val: sw-calibration-access=READ-ONLY, type=ImplementationDataTypes/uint8
    gLockCtrl_u8RRDoorElecRelPWMMotorOutput: invalidation-policy{data-element=gLockCtrl_u8RRDoorElecRelPWMMotorOutput/Val, handle-invalid=DONT-INVALIDATE}
      data Val: sw-calibration-access=READ-ONLY, type=ImplementationDataTypes/uint8
    gLockCtrl_u8RRDoorLockMotorOutput: invalidation-policy{data-element=gLockCtrl_u8RRDoorLockMotorOutput/Val, handle-invalid=DONT-INVALIDATE}
      data Val: sw-calibration-access=READ-ONLY, type=ImplementationDataTypes/uint8
    gLockCtrl_u8RRLockMotorCmd: invalidation-policy{data-element=gLockCtrl_u8RRLockMotorCmd/Val, handle-invalid=DONT-INVALIDATE}
      data Val: sw-calibration-access=READ-ONLY, type=ImplementationDataTypes/uint8
    gLockCtrl_u8RRPowerDoorRelCmd: invalidation-policy{data-element=gLockCtrl_u8RRPowerDoorRelCmd/Val, handle-invalid=DONT-INVALIDATE}
      data Val: sw-calibration-access=READ-ONLY, type=ImplementationDataTypes/uint8
    gLockCtrl_u8RRPowerDoorRelDoneFlag: invalidation-policy{data-element=gLockCtrl_u8RRPowerDoorRelDoneFlag/Val, handle-invalid=DONT-INVALIDATE}
      data Val: sw-calibration-access=READ-ONLY, type=ImplementationDataTypes/uint8
    gLockCtrl_u8RRPowerDoorReq: invalidation-policy{data-element=gLockCtrl_u8RRPowerDoorReq/Val, handle-invalid=DONT-INVALIDATE}
      data Val: sw-calibration-access=READ-ONLY, type=ImplementationDataTypes/uint8
    gLockCtrl_u8TrunkDoorUnlockReq: invalidation-policy{data-element=gLockCtrl_u8TrunkDoorUnlockReq/Val, handle-invalid=DONT-INVALIDATE}
      data Val: sw-calibration-access=READ-ONLY, type=ImplementationDataTypes/uint8
    gPRM_u8PowerDoorCfg: invalidation-policy{data-element=gPRM_u8PowerDoorCfg/Val, handle-invalid=DONT-INVALIDATE}
      data Val: sw-calibration-access=READ-ONLY, type=ImplementationDataTypes/uint8
    gPRM_u8tAjarKeepAwakeCfg: invalidation-policy{data-element=gPRM_u8tAjarKeepAwakeCfg/Val, handle-invalid=DONT-INVALIDATE}
      data Val: sw-calibration-access=READ-ONLY, type=ImplementationDataTypes/uint8
    gPRM_u8tDoorsLockUnlockCfg: invalidation-policy{data-element=gPRM_u8tDoorsLockUnlockCfg/Val, handle-invalid=DONT-INVALIDATE}
      data Val: sw-calibration-access=READ-ONLY, type=ImplementationDataTypes/uint8
    gPRM_u8tFillerCapLockUnlockCfg: invalidation-policy{data-element=gPRM_u8tFillerCapLockUnlockCfg/Val, handle-invalid=DONT-INVALIDATE}
      data Val: sw-calibration-access=READ-ONLY, type=ImplementationDataTypes/uint8
    gPRM_u8tIntervalEmgcUnlockCfg: invalidation-policy{data-element=gPRM_u8tIntervalEmgcUnlockCfg/Val, handle-invalid=DONT-INVALIDATE}
      data Val: sw-calibration-access=READ-ONLY, type=ImplementationDataTypes/uint8
    gPRM_u8tIntervalReverseUnlockCfg: invalidation-policy{data-element=gPRM_u8tIntervalReverseUnlockCfg/Val, handle-invalid=DONT-INVALIDATE}
      data Val: sw-calibration-access=READ-ONLY, type=ImplementationDataTypes/uint8
    gPRM_u8tPowerCinchCfg: invalidation-policy{data-element=gPRM_u8tPowerCinchCfg/Val, handle-invalid=DONT-INVALIDATE}
      data Val: sw-calibration-access=READ-ONLY, type=ImplementationDataTypes/uint8
    gPRM_u8tPowerReleaseCfg: invalidation-policy{data-element=gPRM_u8tPowerReleaseCfg/Val, handle-invalid=DONT-INVALIDATE}
      data Val: sw-calibration-access=READ-ONLY, type=ImplementationDataTypes/uint8
    gPRM_u8tPowerReleaseTimeOutCfg: invalidation-policy{data-element=gPRM_u8tPowerReleaseTimeOutCfg/Val, handle-invalid=DONT-INVALIDATE}
      data Val: sw-calibration-access=READ-ONLY, type=ImplementationDataTypes/uint8
    gPRM_u8tTrunkUnlockCfg: invalidation-policy{data-element=gPRM_u8tTrunkUnlockCfg/Val, handle-invalid=DONT-INVALIDATE}
      data Val: sw-calibration-access=READ-ONLY, type=ImplementationDataTypes/uint8
    gPRM_u8VehicleTypeCfg: invalidation-policy{data-element=gPRM_u8VehicleTypeCfg/Val, handle-invalid=DONT-INVALIDATE}
      data Val: sw-calibration-access=READ-ONLY, type=ImplementationDataTypes/uint8
    gSuctnDoor_bRLInPwrRelsSwt: invalidation-policy{data-element=gSuctnDoor_bRLInPwrRelsSwt/Val, handle-invalid=DONT-INVALIDATE}
      data Val: sw-calibration-access=READ-ONLY, type=ImplementationDataTypes/boolean
    gSuctnDoor_bRLSecLockFbSt: invalidation-policy{data-element=gSuctnDoor_bRLSecLockFbSt/Val, handle-invalid=DONT-INVALIDATE}
      data Val: sw-calibration-access=READ-ONLY, type=ImplementationDataTypes/boolean
    gSuctnDoor_bRRInPwrRlesSwt: invalidation-policy{data-element=gSuctnDoor_bRRInPwrRlesSwt/Val, handle-invalid=DONT-INVALIDATE}
      data Val: sw-calibration-access=READ-ONLY, type=ImplementationDataTypes/boolean
    gSuctnDoor_bRRSecLockFbSt: invalidation-policy{data-element=gSuctnDoor_bRRSecLockFbSt/Val, handle-invalid=DONT-INVALIDATE}
      data Val: sw-calibration-access=READ-ONLY, type=ImplementationDataTypes/boolean
    gVRM_u16BatteryVolt_mv: invalidation-policy{data-element=gVRM_u16BatteryVolt_mv/Val, handle-invalid=DONT-INVALIDATE}
      data Val: sw-calibration-access=READ-ONLY, type=ImplementationDataTypes/uint16
package /UAES/ASW/SwComponentTypes
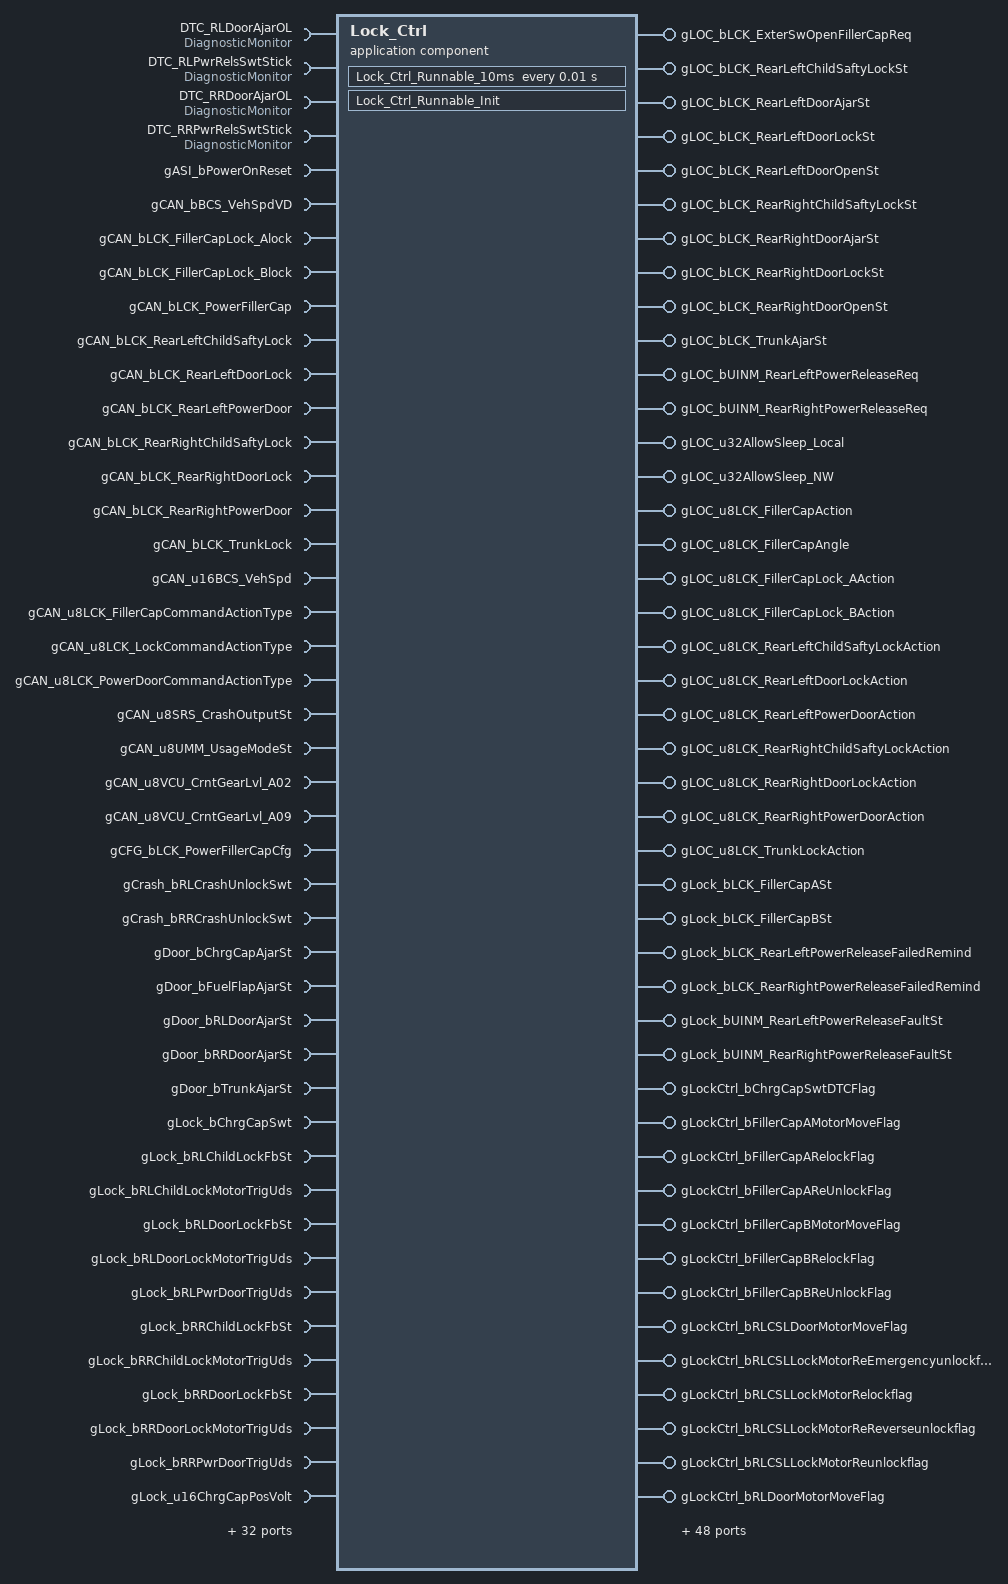
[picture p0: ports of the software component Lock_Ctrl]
  application sw component type Lock_Ctrl
    92 x provide port:
      gLOC_bLCK_ExterSwOpenFillerCapReq: nonqueued-sender-com-spec{data-element=gLOC_bLCK_ExterSwOpenFillerCapReq/Val, init-value=0}, provided-interface=gLOC_bLCK_ExterSwOpenFillerCapReq
      gLOC_bLCK_RearLeftChildSaftyLockSt: nonqueued-sender-com-spec{data-element=gLOC_bLCK_RearLeftChildSaftyLockSt/Val, init-value=0}, provided-interface=gLOC_bLCK_RearLeftChildSaftyLockSt
      gLOC_bLCK_RearLeftDoorAjarSt: nonqueued-sender-com-spec{data-element=gLOC_bLCK_RearLeftDoorAjarSt/Val, init-value=0}, provided-interface=gLOC_bLCK_RearLeftDoorAjarSt
      gLOC_bLCK_RearLeftDoorLockSt: nonqueued-sender-com-spec{data-element=gLOC_bLCK_RearLeftDoorLockSt/Val, init-value=0}, provided-interface=gLOC_bLCK_RearLeftDoorLockSt
      gLOC_bLCK_RearLeftDoorOpenSt: nonqueued-sender-com-spec{data-element=gLOC_bLCK_RearLeftDoorOpenSt/Val, init-value=0}, provided-interface=gLOC_bLCK_RearLeftDoorOpenSt
      gLOC_bLCK_RearRightChildSaftyLockSt: nonqueued-sender-com-spec{data-element=gLOC_bLCK_RearRightChildSaftyLockSt/Val, init-value=0}, provided-interface=gLOC_bLCK_RearRightChildSaftyLockSt
      gLOC_bLCK_RearRightDoorAjarSt: nonqueued-sender-com-spec{data-element=gLOC_bLCK_RearRightDoorAjarSt/Val, init-value=0}, provided-interface=gLOC_bLCK_RearRightDoorAjarSt
      gLOC_bLCK_RearRightDoorLockSt: nonqueued-sender-com-spec{data-element=gLOC_bLCK_RearRightDoorLockSt/Val, init-value=0}, provided-interface=gLOC_bLCK_RearRightDoorLockSt
      gLOC_bLCK_RearRightDoorOpenSt: nonqueued-sender-com-spec{data-element=gLOC_bLCK_RearRightDoorOpenSt/Val, init-value=0}, provided-interface=gLOC_bLCK_RearRightDoorOpenSt
      gLOC_bLCK_TrunkAjarSt: nonqueued-sender-com-spec{data-element=gLOC_bLCK_TrunkAjarSt/Val, init-value=0}, provided-interface=gLOC_bLCK_TrunkAjarSt
      gLOC_bUINM_RearLeftPowerReleaseReq: nonqueued-sender-com-spec{data-element=gLOC_bUINM_RearLeftPowerReleaseReq/Val, init-value=0}, provided-interface=gLOC_bUINM_RearLeftPowerReleaseReq
      gLOC_bUINM_RearRightPowerReleaseReq: nonqueued-sender-com-spec{data-element=gLOC_bUINM_RearRightPowerReleaseReq/Val, init-value=0}, provided-interface=gLOC_bUINM_RearRightPowerReleaseReq
      gLOC_u32AllowSleep_Local: nonqueued-sender-com-spec{data-element=gLOC_u32AllowSleep_Local/Val, init-value=0}, provided-interface=gLOC_u32AllowSleep_Local
      gLOC_u32AllowSleep_NW: nonqueued-sender-com-spec{data-element=gLOC_u32AllowSleep_NW/Val, init-value=0}, provided-interface=gLOC_u32AllowSleep_NW
      gLOC_u8LCK_FillerCapAction: nonqueued-sender-com-spec{data-element=gLOC_u8LCK_FillerCapAction/Val, init-value=0}, provided-interface=gLOC_u8LCK_FillerCapAction
      gLOC_u8LCK_FillerCapAngle: nonqueued-sender-com-spec{data-element=gLOC_u8LCK_FillerCapAngle/Val, init-value=0}, provided-interface=gLOC_u8LCK_FillerCapAngle
      gLOC_u8LCK_FillerCapLock_AAction: nonqueued-sender-com-spec{data-element=gLOC_u8LCK_FillerCapLock_AAction/Val, init-value=0}, provided-interface=gLOC_u8LCK_FillerCapLock_AAction
      gLOC_u8LCK_FillerCapLock_BAction: nonqueued-sender-com-spec{data-element=gLOC_u8LCK_FillerCapLock_BAction/Val, init-value=0}, provided-interface=gLOC_u8LCK_FillerCapLock_BAction
      gLOC_u8LCK_RearLeftChildSaftyLockAction: nonqueued-sender-com-spec{data-element=gLOC_u8LCK_RearLeftChildSaftyLockAction/Val, init-value=0}, provided-interface=gLOC_u8LCK_RearLeftChildSaftyLockAction
      gLOC_u8LCK_RearLeftDoorLockAction: nonqueued-sender-com-spec{data-element=gLOC_u8LCK_RearLeftDoorLockAction/Val, init-value=0}, provided-interface=gLOC_u8LCK_RearLeftDoorLockAction
      gLOC_u8LCK_RearLeftPowerDoorAction: nonqueued-sender-com-spec{data-element=gLOC_u8LCK_RearLeftPowerDoorAction/Val, init-value=0}, provided-interface=gLOC_u8LCK_RearLeftPowerDoorAction
      gLOC_u8LCK_RearRightChildSaftyLockAction: nonqueued-sender-com-spec{data-element=gLOC_u8LCK_RearRightChildSaftyLockAction/Val, init-value=0}, provided-interface=gLOC_u8LCK_RearRightChildSaftyLockAction
      gLOC_u8LCK_RearRightDoorLockAction: nonqueued-sender-com-spec{data-element=gLOC_u8LCK_RearRightDoorLockAction/Val, init-value=0}, provided-interface=gLOC_u8LCK_RearRightDoorLockAction
      gLOC_u8LCK_RearRightPowerDoorAction: nonqueued-sender-com-spec{data-element=gLOC_u8LCK_RearRightPowerDoorAction/Val, init-value=0}, provided-interface=gLOC_u8LCK_RearRightPowerDoorAction
      gLOC_u8LCK_TrunkLockAction: nonqueued-sender-com-spec{data-element=gLOC_u8LCK_TrunkLockAction/Val, init-value=0}, provided-interface=gLOC_u8LCK_TrunkLockAction
      gLock_bLCK_FillerCapASt: nonqueued-sender-com-spec{data-element=gLock_bLCK_FillerCapASt/Val, init-value=0}, provided-interface=gLock_bLCK_FillerCapASt
      gLock_bLCK_FillerCapBSt: nonqueued-sender-com-spec{data-element=gLock_bLCK_FillerCapBSt/Val, init-value=0}, provided-interface=gLock_bLCK_FillerCapBSt
      gLock_bLCK_RearLeftPowerReleaseFailedRemind: nonqueued-sender-com-spec{data-element=gLock_bLCK_RearLeftPowerReleaseFailedRemind/Val, init-value=0}, provided-interface=gLock_bLCK_RearLeftPowerReleaseFailedRemind
      gLock_bLCK_RearRightPowerReleaseFailedRemind: nonqueued-sender-com-spec{data-element=gLock_bLCK_RearRightPowerReleaseFailedRemind/Val, init-value=0}, provided-interface=gLock_bLCK_RearRightPowerReleaseFailedRemind
      gLock_bUINM_RearLeftPowerReleaseFaultSt: nonqueued-sender-com-spec{data-element=gLock_bUINM_RearLeftPowerReleaseFaultSt/Val, init-value=0}, provided-interface=gLock_bUINM_RearLeftPowerReleaseFaultSt
      gLock_bUINM_RearRightPowerReleaseFaultSt: nonqueued-sender-com-spec{data-element=gLock_bUINM_RearRightPowerReleaseFaultSt/Val, init-value=0}, provided-interface=gLock_bUINM_RearRightPowerReleaseFaultSt
      gLockCtrl_bChrgCapSwtDTCFlag: nonqueued-sender-com-spec{data-element=gLockCtrl_bChrgCapSwtDTCFlag/Val, init-value=0}, provided-interface=gLockCtrl_bChrgCapSwtDTCFlag
      gLockCtrl_bFillerCapAMotorMoveFlag: nonqueued-sender-com-spec{data-element=gLockCtrl_bFillerCapAMotorMoveFlag/Val, init-value=0}, provided-interface=gLockCtrl_bFillerCapAMotorMoveFlag
      gLockCtrl_bFillerCapARelockFlag: nonqueued-sender-com-spec{data-element=gLockCtrl_bFillerCapARelockFlag/Val, init-value=0}, provided-interface=gLockCtrl_bFillerCapARelockFlag
      gLockCtrl_bFillerCapAReUnlockFlag: nonqueued-sender-com-spec{data-element=gLockCtrl_bFillerCapAReUnlockFlag/Val, init-value=0}, provided-interface=gLockCtrl_bFillerCapAReUnlockFlag
      gLockCtrl_bFillerCapBMotorMoveFlag: nonqueued-sender-com-spec{data-element=gLockCtrl_bFillerCapBMotorMoveFlag/Val, init-value=0}, provided-interface=gLockCtrl_bFillerCapBMotorMoveFlag
      gLockCtrl_bFillerCapBRelockFlag: nonqueued-sender-com-spec{data-element=gLockCtrl_bFillerCapBRelockFlag/Val, init-value=0}, provided-interface=gLockCtrl_bFillerCapBRelockFlag
      gLockCtrl_bFillerCapBReUnlockFlag: nonqueued-sender-com-spec{data-element=gLockCtrl_bFillerCapBReUnlockFlag/Val, init-value=0}, provided-interface=gLockCtrl_bFillerCapBReUnlockFlag
      gLockCtrl_bRLCSLDoorMotorMoveFlag: nonqueued-sender-com-spec{data-element=gLockCtrl_bRLCSLDoorMotorMoveFlag/Val, init-value=0}, provided-interface=gLockCtrl_bRLCSLDoorMotorMoveFlag
      gLockCtrl_bRLCSLLockMotorReEmergencyunlockflag: nonqueued-sender-com-spec{data-element=gLockCtrl_bRLCSLLockMotorReEmergencyunlockflag/Val, init-value=0}, provided-interface=gLockCtrl_bRLCSLLockMotorReEmergencyunlockflag
      gLockCtrl_bRLCSLLockMotorRelockflag: nonqueued-sender-com-spec{data-element=gLockCtrl_bRLCSLLockMotorRelockflag/Val, init-value=0}, provided-interface=gLockCtrl_bRLCSLLockMotorRelockflag
      gLockCtrl_bRLCSLLockMotorReReverseunlockflag: nonqueued-sender-com-spec{data-element=gLockCtrl_bRLCSLLockMotorReReverseunlockflag/Val, init-value=0}, provided-interface=gLockCtrl_bRLCSLLockMotorReReverseunlockflag
      gLockCtrl_bRLCSLLockMotorReunlockflag: nonqueued-sender-com-spec{data-element=gLockCtrl_bRLCSLLockMotorReunlockflag/Val, init-value=0}, provided-interface=gLockCtrl_bRLCSLLockMotorReunlockflag
      gLockCtrl_bRLDoorMotorMoveFlag: nonqueued-sender-com-spec{data-element=gLockCtrl_bRLDoorMotorMoveFlag/Val, init-value=0}, provided-interface=gLockCtrl_bRLDoorMotorMoveFlag
      gLockCtrl_bRLLockMotorReEmergencyunlockflag: nonqueued-sender-com-spec{data-element=gLockCtrl_bRLLockMotorReEmergencyunlockflag/Val, init-value=0}, provided-interface=gLockCtrl_bRLLockMotorReEmergencyunlockflag
      gLockCtrl_bRLLockMotorRelockflag: nonqueued-sender-com-spec{data-element=gLockCtrl_bRLLockMotorRelockflag/Val, init-value=0}, provided-interface=gLockCtrl_bRLLockMotorRelockflag
      gLockCtrl_bRLLockMotorReReverseunlockflag: nonqueued-sender-com-spec{data-element=gLockCtrl_bRLLockMotorReReverseunlockflag/Val, init-value=0}, provided-interface=gLockCtrl_bRLLockMotorReReverseunlockflag
      gLockCtrl_bRLLockMotorReunlockflag: nonqueued-sender-com-spec{data-element=gLockCtrl_bRLLockMotorReunlockflag/Val, init-value=0}, provided-interface=gLockCtrl_bRLLockMotorReunlockflag
      gLockCtrl_bRLPowerDoorRelsMotorMoveFlag: nonqueued-sender-com-spec{data-element=gLockCtrl_bRLPowerDoorRelsMotorMoveFlag/Val, init-value=0}, provided-interface=gLockCtrl_bRLPowerDoorRelsMotorMoveFlag
      gLockCtrl_bRLPowerDoorReReleaseflag: nonqueued-sender-com-spec{data-element=gLockCtrl_bRLPowerDoorReReleaseflag/Val, init-value=0}, provided-interface=gLockCtrl_bRLPowerDoorReReleaseflag
      gLockCtrl_bRLPowerReleaseSwDTCFlag: nonqueued-sender-com-spec{data-element=gLockCtrl_bRLPowerReleaseSwDTCFlag/Val, init-value=0}, provided-interface=gLockCtrl_bRLPowerReleaseSwDTCFlag
      gLockCtrl_bRRCSLDoorMotorMoveFlag: nonqueued-sender-com-spec{data-element=gLockCtrl_bRRCSLDoorMotorMoveFlag/Val, init-value=0}, provided-interface=gLockCtrl_bRRCSLDoorMotorMoveFlag
      gLockCtrl_bRRCSLLockMotorReEmergencyunlockflag: nonqueued-sender-com-spec{data-element=gLockCtrl_bRRCSLLockMotorReEmergencyunlockflag/Val, init-value=0}, provided-interface=gLockCtrl_bRRCSLLockMotorReEmergencyunlockflag
      gLockCtrl_bRRCSLLockMotorRelockflag: nonqueued-sender-com-spec{data-element=gLockCtrl_bRRCSLLockMotorRelockflag/Val, init-value=0}, provided-interface=gLockCtrl_bRRCSLLockMotorRelockflag
      gLockCtrl_bRRCSLLockMotorReReverseunlockflag: nonqueued-sender-com-spec{data-element=gLockCtrl_bRRCSLLockMotorReReverseunlockflag/Val, init-value=0}, provided-interface=gLockCtrl_bRRCSLLockMotorReReverseunlockflag
      gLockCtrl_bRRCSLLockMotorReunlockflag: nonqueued-sender-com-spec{data-element=gLockCtrl_bRRCSLLockMotorReunlockflag/Val, init-value=0}, provided-interface=gLockCtrl_bRRCSLLockMotorReunlockflag
      gLockCtrl_bRRDoorMotorMoveFlag: nonqueued-sender-com-spec{data-element=gLockCtrl_bRRDoorMotorMoveFlag/Val, init-value=0}, provided-interface=gLockCtrl_bRRDoorMotorMoveFlag
      gLockCtrl_bRRLockMotorReEmergencyunlockflag: nonqueued-sender-com-spec{data-element=gLockCtrl_bRRLockMotorReEmergencyunlockflag/Val, init-value=0}, provided-interface=gLockCtrl_bRRLockMotorReEmergencyunlockflag
      gLockCtrl_bRRLockMotorRelockflag: nonqueued-sender-com-spec{data-element=gLockCtrl_bRRLockMotorRelockflag/Val, init-value=0}, provided-interface=gLockCtrl_bRRLockMotorRelockflag
      gLockCtrl_bRRLockMotorReReverseunlockflag: nonqueued-sender-com-spec{data-element=gLockCtrl_bRRLockMotorReReverseunlockflag/Val, init-value=0}, provided-interface=gLockCtrl_bRRLockMotorReReverseunlockflag
      gLockCtrl_bRRLockMotorReunlockflag: nonqueued-sender-com-spec{data-element=gLockCtrl_bRRLockMotorReunlockflag/Val, init-value=0}, provided-interface=gLockCtrl_bRRLockMotorReunlockflag
      gLockCtrl_bRRPowerDoorRelsMotorMoveFlag: nonqueued-sender-com-spec{data-element=gLockCtrl_bRRPowerDoorRelsMotorMoveFlag/Val, init-value=0}, provided-interface=gLockCtrl_bRRPowerDoorRelsMotorMoveFlag
      gLockCtrl_bRRPowerDoorReReleaseflag: nonqueued-sender-com-spec{data-element=gLockCtrl_bRRPowerDoorReReleaseflag/Val, init-value=0}, provided-interface=gLockCtrl_bRRPowerDoorReReleaseflag
      gLockCtrl_bRRPowerReleaseSwDTCFlag: nonqueued-sender-com-spec{data-element=gLockCtrl_bRRPowerReleaseSwDTCFlag/Val, init-value=0}, provided-interface=gLockCtrl_bRRPowerReleaseSwDTCFlag
      gLockCtrl_bTrunkMotorMoveFlag: nonqueued-sender-com-spec{data-element=gLockCtrl_bTrunkMotorMoveFlag/Val, init-value=0}, provided-interface=gLockCtrl_bTrunkMotorMoveFlag
      gLockCtrl_bTrunkReUnlockFlag: nonqueued-sender-com-spec{data-element=gLockCtrl_bTrunkReUnlockFlag/Val, init-value=0}, provided-interface=gLockCtrl_bTrunkReUnlockFlag
      gLockCtrl_u8BootLockMotorOutput: nonqueued-sender-com-spec{data-element=gLockCtrl_u8BootLockMotorOutput/Val, init-value=0}, provided-interface=gLockCtrl_u8BootLockMotorOutput
      gLockCtrl_u8ChrgCapLockMotorOutput: nonqueued-sender-com-spec{data-element=gLockCtrl_u8ChrgCapLockMotorOutput/Val, init-value=0}, provided-interface=gLockCtrl_u8ChrgCapLockMotorOutput
      gLockCtrl_u8FillerCapAMotorCmd: nonqueued-sender-com-spec{data-element=gLockCtrl_u8FillerCapAMotorCmd/Val, init-value=0}, provided-interface=gLockCtrl_u8FillerCapAMotorCmd
      gLockCtrl_u8FillerCapBMotorCmd: nonqueued-sender-com-spec{data-element=gLockCtrl_u8FillerCapBMotorCmd/Val, init-value=0}, provided-interface=gLockCtrl_u8FillerCapBMotorCmd
      gLockCtrl_u8FillerCapLockReqA: nonqueued-sender-com-spec{data-element=gLockCtrl_u8FillerCapLockReqA/Val, init-value=0}, provided-interface=gLockCtrl_u8FillerCapLockReqA
      gLockCtrl_u8FillerCapLockReqB: nonqueued-sender-com-spec{data-element=gLockCtrl_u8FillerCapLockReqB/Val, init-value=0}, provided-interface=gLockCtrl_u8FillerCapLockReqB
      gLockCtrl_u8OilTankLockMotorOutput: nonqueued-sender-com-spec{data-element=gLockCtrl_u8OilTankLockMotorOutput/Val, init-value=0}, provided-interface=gLockCtrl_u8OilTankLockMotorOutput
      gLockCtrl_u8RLChildLockMotorOutput: nonqueued-sender-com-spec{data-element=gLockCtrl_u8RLChildLockMotorOutput/Val, init-value=0}, provided-interface=gLockCtrl_u8RLChildLockMotorOutput
      gLockCtrl_u8RLCSLLockMotorCmd: nonqueued-sender-com-spec{data-element=gLockCtrl_u8RLCSLLockMotorCmd/Val, init-value=0}, provided-interface=gLockCtrl_u8RLCSLLockMotorCmd
      gLockCtrl_u8RLDoorElecRelMotorOutput: nonqueued-sender-com-spec{data-element=gLockCtrl_u8RLDoorElecRelMotorOutput/Val, init-value=0}, provided-interface=gLockCtrl_u8RLDoorElecRelMotorOutput
      gLockCtrl_u8RLDoorElecRelPWMMotorOutput: nonqueued-sender-com-spec{data-element=gLockCtrl_u8RLDoorElecRelPWMMotorOutput/Val, init-value=0}, provided-interface=gLockCtrl_u8RLDoorElecRelPWMMotorOutput
      gLockCtrl_u8RLDoorLockMotorOutput: nonqueued-sender-com-spec{data-element=gLockCtrl_u8RLDoorLockMotorOutput/Val, init-value=0}, provided-interface=gLockCtrl_u8RLDoorLockMotorOutput
      gLockCtrl_u8RLLockMotorCmd: nonqueued-sender-com-spec{data-element=gLockCtrl_u8RLLockMotorCmd/Val, init-value=0}, provided-interface=gLockCtrl_u8RLLockMotorCmd
      gLockCtrl_u8RLPowerDoorRelCmd: nonqueued-sender-com-spec{data-element=gLockCtrl_u8RLPowerDoorRelCmd/Val, init-value=0}, provided-interface=gLockCtrl_u8RLPowerDoorRelCmd
      gLockCtrl_u8RLPowerDoorRelDoneFlag: nonqueued-sender-com-spec{data-element=gLockCtrl_u8RLPowerDoorRelDoneFlag/Val, init-value=0}, provided-interface=gLockCtrl_u8RLPowerDoorRelDoneFlag
      gLockCtrl_u8RLPowerDoorReq: nonqueued-sender-com-spec{data-element=gLockCtrl_u8RLPowerDoorReq/Val, init-value=0}, provided-interface=gLockCtrl_u8RLPowerDoorReq
      gLockCtrl_u8RRChildLockMotorOutput: nonqueued-sender-com-spec{data-element=gLockCtrl_u8RRChildLockMotorOutput/Val, init-value=0}, provided-interface=gLockCtrl_u8RRChildLockMotorOutput
      gLockCtrl_u8RRCSLLockMotorCmd: nonqueued-sender-com-spec{data-element=gLockCtrl_u8RRCSLLockMotorCmd/Val, init-value=0}, provided-interface=gLockCtrl_u8RRCSLLockMotorCmd
      gLockCtrl_u8RRDoorElecRelMotorOutput: nonqueued-sender-com-spec{data-element=gLockCtrl_u8RRDoorElecRelMotorOutput/Val, init-value=0}, provided-interface=gLockCtrl_u8RRDoorElecRelMotorOutput
      gLockCtrl_u8RRDoorElecRelPWMMotorOutput: nonqueued-sender-com-spec{data-element=gLockCtrl_u8RRDoorElecRelPWMMotorOutput/Val, init-value=0}, provided-interface=gLockCtrl_u8RRDoorElecRelPWMMotorOutput
      gLockCtrl_u8RRDoorLockMotorOutput: nonqueued-sender-com-spec{data-element=gLockCtrl_u8RRDoorLockMotorOutput/Val, init-value=0}, provided-interface=gLockCtrl_u8RRDoorLockMotorOutput
      gLockCtrl_u8RRLockMotorCmd: nonqueued-sender-com-spec{data-element=gLockCtrl_u8RRLockMotorCmd/Val, init-value=0}, provided-interface=gLockCtrl_u8RRLockMotorCmd
      gLockCtrl_u8RRPowerDoorRelCmd: nonqueued-sender-com-spec{data-element=gLockCtrl_u8RRPowerDoorRelCmd/Val, init-value=0}, provided-interface=gLockCtrl_u8RRPowerDoorRelCmd
      gLockCtrl_u8RRPowerDoorRelDoneFlag: nonqueued-sender-com-spec{data-element=gLockCtrl_u8RRPowerDoorRelDoneFlag/Val, init-value=0}, provided-interface=gLockCtrl_u8RRPowerDoorRelDoneFlag
      gLockCtrl_u8RRPowerDoorReq: nonqueued-sender-com-spec{data-element=gLockCtrl_u8RRPowerDoorReq/Val, init-value=0}, provided-interface=gLockCtrl_u8RRPowerDoorReq
      gLockCtrl_u8TrunkDoorUnlockReq: nonqueued-sender-com-spec{data-element=gLockCtrl_u8TrunkDoorUnlockReq/Val, init-value=0}, provided-interface=gLockCtrl_u8TrunkDoorUnlockReq
    76 x require port:
      DTC_RLDoorAjarOL: required-interface=DiagnosticMonitor
        required-com-specs:
          GetDTCOfEvent
          GetEventExtendedDataRecordEx
          GetEventFailed
          GetEventFreezeFrameDataEx
          GetEventStatus
          GetEventTested
          GetEventUdsStatus
          GetFaultDetectionCounter
          ResetEventDebounceStatus
          ResetEventStatus
          SetEventStatus
      DTC_RLPwrRelsSwtStick: required-interface=DiagnosticMonitor
        required-com-specs:
          GetDTCOfEvent
          GetEventExtendedDataRecordEx
          GetEventFailed
          GetEventFreezeFrameDataEx
          GetEventStatus
          GetEventTested
          GetEventUdsStatus
          GetFaultDetectionCounter
          ResetEventDebounceStatus
          ResetEventStatus
          SetEventStatus
      DTC_RRDoorAjarOL: required-interface=DiagnosticMonitor
        required-com-specs:
          GetDTCOfEvent
          GetEventExtendedDataRecordEx
          GetEventFailed
          GetEventFreezeFrameDataEx
          GetEventStatus
          GetEventTested
          GetEventUdsStatus
          GetFaultDetectionCounter
          ResetEventDebounceStatus
          ResetEventStatus
          SetEventStatus
      DTC_RRPwrRelsSwtStick: required-interface=DiagnosticMonitor
        required-com-specs:
          GetDTCOfEvent
          GetEventExtendedDataRecordEx
          GetEventFailed
          GetEventFreezeFrameDataEx
          GetEventStatus
          GetEventTested
          GetEventUdsStatus
          GetFaultDetectionCounter
          ResetEventDebounceStatus
          ResetEventStatus
          SetEventStatus
      gASI_bPowerOnReset: nonqueued-receiver-com-spec{data-element=gASI_bPowerOnReset/Val, filter=data-filter-type=ALWAYS, init-value=0}, required-interface=gASI_bPowerOnReset
      gCAN_bBCS_VehSpdVD: nonqueued-receiver-com-spec{data-element=gCAN_bBCS_VehSpdVD/Val, filter=data-filter-type=ALWAYS, init-value=0}, required-interface=gCAN_bBCS_VehSpdVD
      gCAN_bLCK_FillerCapLock_Alock: nonqueued-receiver-com-spec{data-element=gCAN_bLCK_FillerCapLock_Alock/Val, filter=data-filter-type=ALWAYS, init-value=0}, required-interface=gCAN_bLCK_FillerCapLock_Alock
      gCAN_bLCK_FillerCapLock_Block: nonqueued-receiver-com-spec{data-element=gCAN_bLCK_FillerCapLock_Block/Val, filter=data-filter-type=ALWAYS, init-value=0}, required-interface=gCAN_bLCK_FillerCapLock_Block
      gCAN_bLCK_PowerFillerCap: nonqueued-receiver-com-spec{data-element=gCAN_bLCK_PowerFillerCap/Val, filter=data-filter-type=ALWAYS, init-value=0}, required-interface=gCAN_bLCK_PowerFillerCap
      gCAN_bLCK_RearLeftChildSaftyLock: nonqueued-receiver-com-spec{data-element=gCAN_bLCK_RearLeftChildSaftyLock/Val, filter=data-filter-type=ALWAYS, init-value=0}, required-interface=gCAN_bLCK_RearLeftChildSaftyLock
      gCAN_bLCK_RearLeftDoorLock: nonqueued-receiver-com-spec{data-element=gCAN_bLCK_RearLeftDoorLock/Val, filter=data-filter-type=ALWAYS, init-value=0}, required-interface=gCAN_bLCK_RearLeftDoorLock
      gCAN_bLCK_RearLeftPowerDoor: nonqueued-receiver-com-spec{data-element=gCAN_bLCK_RearLeftPowerDoor/Val, filter=data-filter-type=ALWAYS, init-value=0}, required-interface=gCAN_bLCK_RearLeftPowerDoor
      gCAN_bLCK_RearRightChildSaftyLock: nonqueued-receiver-com-spec{data-element=gCAN_bLCK_RearRightChildSaftyLock/Val, filter=data-filter-type=ALWAYS, init-value=0}, required-interface=gCAN_bLCK_RearRightChildSaftyLock
      gCAN_bLCK_RearRightDoorLock: nonqueued-receiver-com-spec{data-element=gCAN_bLCK_RearRightDoorLock/Val, filter=data-filter-type=ALWAYS, init-value=0}, required-interface=gCAN_bLCK_RearRightDoorLock
      gCAN_bLCK_RearRightPowerDoor: nonqueued-receiver-com-spec{data-element=gCAN_bLCK_RearRightPowerDoor/Val, filter=data-filter-type=ALWAYS, init-value=0}, required-interface=gCAN_bLCK_RearRightPowerDoor
      gCAN_bLCK_TrunkLock: nonqueued-receiver-com-spec{data-element=gCAN_bLCK_TrunkLock/Val, filter=data-filter-type=ALWAYS, init-value=0}, required-interface=gCAN_bLCK_TrunkLock
      gCAN_u16BCS_VehSpd: nonqueued-receiver-com-spec{data-element=gCAN_u16BCS_VehSpd/Val, filter=data-filter-type=ALWAYS, init-value=0}, required-interface=gCAN_u16BCS_VehSpd
      gCAN_u8LCK_FillerCapCommandActionType: nonqueued-receiver-com-spec{data-element=gCAN_u8LCK_FillerCapCommandActionType/Val, filter=data-filter-type=ALWAYS, init-value=0}, required-interface=gCAN_u8LCK_FillerCapCommandActionType
      gCAN_u8LCK_LockCommandActionType: nonqueued-receiver-com-spec{data-element=gCAN_u8LCK_LockCommandActionType/Val, filter=data-filter-type=ALWAYS, init-value=0}, required-interface=gCAN_u8LCK_LockCommandActionType
      gCAN_u8LCK_PowerDoorCommandActionType: nonqueued-receiver-com-spec{data-element=gCAN_u8LCK_PowerDoorCommandActionType/Val, filter=data-filter-type=ALWAYS, init-value=0}, required-interface=gCAN_u8LCK_PowerDoorCommandActionType
      gCAN_u8SRS_CrashOutputSt: nonqueued-receiver-com-spec{data-element=gCAN_u8SRS_CrashOutputSt/Val, filter=data-filter-type=ALWAYS, init-value=0}, required-interface=gCAN_u8SRS_CrashOutputSt
      gCAN_u8UMM_UsageModeSt: nonqueued-receiver-com-spec{data-element=gCAN_u8UMM_UsageModeSt/Val, filter=data-filter-type=ALWAYS, init-value=0}, required-interface=gCAN_u8UMM_UsageModeSt
      gCAN_u8VCU_CrntGearLvl_A02: nonqueued-receiver-com-spec{data-element=gCAN_u8VCU_CrntGearLvl_A02/Val, filter=data-filter-type=ALWAYS, init-value=0}, required-interface=gCAN_u8VCU_CrntGearLvl_A02
      gCAN_u8VCU_CrntGearLvl_A09: nonqueued-receiver-com-spec{data-element=gCAN_u8VCU_CrntGearLvl_A09/Val, filter=data-filter-type=ALWAYS, init-value=0}, required-interface=gCAN_u8VCU_CrntGearLvl_A09
      gCFG_bLCK_PowerFillerCapCfg: nonqueued-receiver-com-spec{data-element=gCFG_bLCK_PowerFillerCapCfg/Val, filter=data-filter-type=ALWAYS, init-value=0}, required-interface=gCFG_bLCK_PowerFillerCapCfg
      gCrash_bRLCrashUnlockSwt: nonqueued-receiver-com-spec{data-element=gCrash_bRLCrashUnlockSwt/Val, filter=data-filter-type=ALWAYS, init-value=0}, required-interface=gCrash_bRLCrashUnlockSwt
      gCrash_bRRCrashUnlockSwt: nonqueued-receiver-com-spec{data-element=gCrash_bRRCrashUnlockSwt/Val, filter=data-filter-type=ALWAYS, init-value=0}, required-interface=gCrash_bRRCrashUnlockSwt
      gDoor_bChrgCapAjarSt: nonqueued-receiver-com-spec{data-element=gDoor_bChrgCapAjarSt/Val, filter=data-filter-type=ALWAYS, init-value=0}, required-interface=gDoor_bChrgCapAjarSt
      gDoor_bFuelFlapAjarSt: nonqueued-receiver-com-spec{data-element=gDoor_bFuelFlapAjarSt/Val, filter=data-filter-type=ALWAYS, init-value=0}, required-interface=gDoor_bFuelFlapAjarSt
      gDoor_bRLDoorAjarSt: nonqueued-receiver-com-spec{data-element=gDoor_bRLDoorAjarSt/Val, filter=data-filter-type=ALWAYS, init-value=0}, required-interface=gDoor_bRLDoorAjarSt
      gDoor_bRRDoorAjarSt: nonqueued-receiver-com-spec{data-element=gDoor_bRRDoorAjarSt/Val, filter=data-filter-type=ALWAYS, init-value=0}, required-interface=gDoor_bRRDoorAjarSt
      gDoor_bTrunkAjarSt: nonqueued-receiver-com-spec{data-element=gDoor_bTrunkAjarSt/Val, filter=data-filter-type=ALWAYS, init-value=0}, required-interface=gDoor_bTrunkAjarSt
      gLock_bChrgCapSwt: nonqueued-receiver-com-spec{data-element=gLock_bChrgCapSwt/Val, filter=data-filter-type=ALWAYS, init-value=0}, required-interface=gLock_bChrgCapSwt
      gLock_bRLChildLockFbSt: nonqueued-receiver-com-spec{data-element=gLock_bRLChildLockFbSt/Val, filter=data-filter-type=ALWAYS, init-value=0}, required-interface=gLock_bRLChildLockFbSt
      gLock_bRLChildLockMotorTrigUds: nonqueued-receiver-com-spec{data-element=gLock_bRLChildLockMotorTrigUds/Val, filter=data-filter-type=ALWAYS, init-value=0}, required-interface=gLock_bRLChildLockMotorTrigUds
      gLock_bRLDoorLockFbSt: nonqueued-receiver-com-spec{data-element=gLock_bRLDoorLockFbSt/Val, filter=data-filter-type=ALWAYS, init-value=0}, required-interface=gLock_bRLDoorLockFbSt
      gLock_bRLDoorLockMotorTrigUds: nonqueued-receiver-com-spec{data-element=gLock_bRLDoorLockMotorTrigUds/Val, filter=data-filter-type=ALWAYS, init-value=0}, required-interface=gLock_bRLDoorLockMotorTrigUds
      gLock_bRLPwrDoorTrigUds: nonqueued-receiver-com-spec{data-element=gLock_bRLPwrDoorTrigUds/Val, filter=data-filter-type=ALWAYS, init-value=0}, required-interface=gLock_bRLPwrDoorTrigUds
      gLock_bRRChildLockFbSt: nonqueued-receiver-com-spec{data-element=gLock_bRRChildLockFbSt/Val, filter=data-filter-type=ALWAYS, init-value=0}, required-interface=gLock_bRRChildLockFbSt
      gLock_bRRChildLockMotorTrigUds: nonqueued-receiver-com-spec{data-element=gLock_bRRChildLockMotorTrigUds/Val, filter=data-filter-type=ALWAYS, init-value=0}, required-interface=gLock_bRRChildLockMotorTrigUds
      gLock_bRRDoorLockFbSt: nonqueued-receiver-com-spec{data-element=gLock_bRRDoorLockFbSt/Val, filter=data-filter-type=ALWAYS, init-value=0}, required-interface=gLock_bRRDoorLockFbSt
      gLock_bRRDoorLockMotorTrigUds: nonqueued-receiver-com-spec{data-element=gLock_bRRDoorLockMotorTrigUds/Val, filter=data-filter-type=ALWAYS, init-value=0}, required-interface=gLock_bRRDoorLockMotorTrigUds
      gLock_bRRPwrDoorTrigUds: nonqueued-receiver-com-spec{data-element=gLock_bRRPwrDoorTrigUds/Val, filter=data-filter-type=ALWAYS, init-value=0}, required-interface=gLock_bRRPwrDoorTrigUds
      gLock_u16ChrgCapPosVolt: nonqueued-receiver-com-spec{data-element=gLock_u16ChrgCapPosVolt/Val, filter=data-filter-type=ALWAYS, init-value=0}, required-interface=gLock_u16ChrgCapPosVolt
      gLock_u8BootLockMotorPs: nonqueued-receiver-com-spec{data-element=gLock_u8BootLockMotorPs/Val, filter=data-filter-type=ALWAYS, init-value=0}, required-interface=gLock_u8BootLockMotorPs
      gLock_u8ChrgCapLockMotorPs: nonqueued-receiver-com-spec{data-element=gLock_u8ChrgCapLockMotorPs/Val, filter=data-filter-type=ALWAYS, init-value=0}, required-interface=gLock_u8ChrgCapLockMotorPs
      gLock_u8DiagEnbCnd: nonqueued-receiver-com-spec{data-element=gLock_u8DiagEnbCnd/Val, filter=data-filter-type=ALWAYS, init-value=0}, required-interface=gLock_u8DiagEnbCnd
      gLock_u8OilTankLockMotorPs: nonqueued-receiver-com-spec{data-element=gLock_u8OilTankLockMotorPs/Val, filter=data-filter-type=ALWAYS, init-value=0}, required-interface=gLock_u8OilTankLockMotorPs
      gLock_u8RLChildLockMotorPs: nonqueued-receiver-com-spec{data-element=gLock_u8RLChildLockMotorPs/Val, filter=data-filter-type=ALWAYS, init-value=0}, required-interface=gLock_u8RLChildLockMotorPs
      gLock_u8RLChildLockMotorUds: nonqueued-receiver-com-spec{data-element=gLock_u8RLChildLockMotorUds/Val, filter=data-filter-type=ALWAYS, init-value=0}, required-interface=gLock_u8RLChildLockMotorUds
      gLock_u8RLDoorLockMotorPs: nonqueued-receiver-com-spec{data-element=gLock_u8RLDoorLockMotorPs/Val, filter=data-filter-type=ALWAYS, init-value=0}, required-interface=gLock_u8RLDoorLockMotorPs
      gLock_u8RLDoorLockMotorUds: nonqueued-receiver-com-spec{data-element=gLock_u8RLDoorLockMotorUds/Val, filter=data-filter-type=ALWAYS, init-value=0}, required-interface=gLock_u8RLDoorLockMotorUds
      gLock_u8RLPwrDoorUds: nonqueued-receiver-com-spec{data-element=gLock_u8RLPwrDoorUds/Val, filter=data-filter-type=ALWAYS, init-value=0}, required-interface=gLock_u8RLPwrDoorUds
      gLock_u8RLPwrRelsMotorPs: nonqueued-receiver-com-spec{data-element=gLock_u8RLPwrRelsMotorPs/Val, filter=data-filter-type=ALWAYS, init-value=0}, required-interface=gLock_u8RLPwrRelsMotorPs
      gLock_u8RRChildLockMotorPs: nonqueued-receiver-com-spec{data-element=gLock_u8RRChildLockMotorPs/Val, filter=data-filter-type=ALWAYS, init-value=0}, required-interface=gLock_u8RRChildLockMotorPs
      gLock_u8RRChildLockMotorUds: nonqueued-receiver-com-spec{data-element=gLock_u8RRChildLockMotorUds/Val, filter=data-filter-type=ALWAYS, init-value=0}, required-interface=gLock_u8RRChildLockMotorUds
      gLock_u8RRDoorLockMotorPs: nonqueued-receiver-com-spec{data-element=gLock_u8RRDoorLockMotorPs/Val, filter=data-filter-type=ALWAYS, init-value=0}, required-interface=gLock_u8RRDoorLockMotorPs
      gLock_u8RRDoorLockMotorUds: nonqueued-receiver-com-spec{data-element=gLock_u8RRDoorLockMotorUds/Val, filter=data-filter-type=ALWAYS, init-value=0}, required-interface=gLock_u8RRDoorLockMotorUds
      gLock_u8RRPwrDoorUds: nonqueued-receiver-com-spec{data-element=gLock_u8RRPwrDoorUds/Val, filter=data-filter-type=ALWAYS, init-value=0}, required-interface=gLock_u8RRPwrDoorUds
      gLock_u8RRPwrRelsMotorPs: nonqueued-receiver-com-spec{data-element=gLock_u8RRPwrRelsMotorPs/Val, filter=data-filter-type=ALWAYS, init-value=0}, required-interface=gLock_u8RRPwrRelsMotorPs
      gPRM_u8PowerDoorCfg: nonqueued-receiver-com-spec{data-element=gPRM_u8PowerDoorCfg/Val, filter=data-filter-type=ALWAYS, init-value=0}, required-interface=gPRM_u8PowerDoorCfg
      gPRM_u8tAjarKeepAwakeCfg: nonqueued-receiver-com-spec{data-element=gPRM_u8tAjarKeepAwakeCfg/Val, filter=data-filter-type=ALWAYS, init-value=0}, required-interface=gPRM_u8tAjarKeepAwakeCfg
      gPRM_u8tDoorsLockUnlockCfg: nonqueued-receiver-com-spec{data-element=gPRM_u8tDoorsLockUnlockCfg/Val, filter=data-filter-type=ALWAYS, init-value=0}, required-interface=gPRM_u8tDoorsLockUnlockCfg
      gPRM_u8tFillerCapLockUnlockCfg: nonqueued-receiver-com-spec{data-element=gPRM_u8tFillerCapLockUnlockCfg/Val, filter=data-filter-type=ALWAYS, init-value=0}, required-interface=gPRM_u8tFillerCapLockUnlockCfg
      gPRM_u8tIntervalEmgcUnlockCfg: nonqueued-receiver-com-spec{data-element=gPRM_u8tIntervalEmgcUnlockCfg/Val, filter=data-filter-type=ALWAYS, init-value=0}, required-interface=gPRM_u8tIntervalEmgcUnlockCfg
      gPRM_u8tIntervalReverseUnlockCfg: nonqueued-receiver-com-spec{data-element=gPRM_u8tIntervalReverseUnlockCfg/Val, filter=data-filter-type=ALWAYS, init-value=0}, required-interface=gPRM_u8tIntervalReverseUnlockCfg
      gPRM_u8tPowerCinchCfg: nonqueued-receiver-com-spec{data-element=gPRM_u8tPowerCinchCfg/Val, filter=data-filter-type=ALWAYS, init-value=0}, required-interface=gPRM_u8tPowerCinchCfg
      gPRM_u8tPowerReleaseCfg: nonqueued-receiver-com-spec{data-element=gPRM_u8tPowerReleaseCfg/Val, filter=data-filter-type=ALWAYS, init-value=0}, required-interface=gPRM_u8tPowerReleaseCfg
      gPRM_u8tPowerReleaseTimeOutCfg: nonqueued-receiver-com-spec{data-element=gPRM_u8tPowerReleaseTimeOutCfg/Val, filter=data-filter-type=ALWAYS, init-value=0}, required-interface=gPRM_u8tPowerReleaseTimeOutCfg
      gPRM_u8tTrunkUnlockCfg: nonqueued-receiver-com-spec{data-element=gPRM_u8tTrunkUnlockCfg/Val, filter=data-filter-type=ALWAYS, init-value=0}, required-interface=gPRM_u8tTrunkUnlockCfg
      gPRM_u8VehicleTypeCfg: nonqueued-receiver-com-spec{data-element=gPRM_u8VehicleTypeCfg/Val, filter=data-filter-type=ALWAYS, init-value=0}, required-interface=gPRM_u8VehicleTypeCfg
      gSuctnDoor_bRLInPwrRelsSwt: nonqueued-receiver-com-spec{data-element=gSuctnDoor_bRLInPwrRelsSwt/Val, filter=data-filter-type=ALWAYS, init-value=0}, required-interface=gSuctnDoor_bRLInPwrRelsSwt
      gSuctnDoor_bRLSecLockFbSt: nonqueued-receiver-com-spec{data-element=gSuctnDoor_bRLSecLockFbSt/Val, filter=data-filter-type=ALWAYS, init-value=0}, required-interface=gSuctnDoor_bRLSecLockFbSt
      gSuctnDoor_bRRInPwrRlesSwt: nonqueued-receiver-com-spec{data-element=gSuctnDoor_bRRInPwrRlesSwt/Val, filter=data-filter-type=ALWAYS, init-value=0}, required-interface=gSuctnDoor_bRRInPwrRlesSwt
      gSuctnDoor_bRRSecLockFbSt: nonqueued-receiver-com-spec{data-element=gSuctnDoor_bRRSecLockFbSt/Val, filter=data-filter-type=ALWAYS, init-value=0}, required-interface=gSuctnDoor_bRRSecLockFbSt
      gVRM_u16BatteryVolt_mv: nonqueued-receiver-com-spec{data-element=gVRM_u16BatteryVolt_mv/Val, filter=data-filter-type=ALWAYS, init-value=0}, required-interface=gVRM_u16BatteryVolt_mv
    behavior Lock_Ctrl_InternalBehavior: data-type-mapping=[DTMS_LOC_10ms, DTMS_Lock_Ctrl]
      timing event TMT_Lock_Ctrl_Runnable_10ms: start-on-event=Lock_Ctrl_Runnable_10ms, period=0.01
      init event Lock_Ctrl_InitEvent: start-on-event=Lock_Ctrl_Runnable_Init
      runnable Lock_Ctrl_Runnable_10ms
        data-receive-point-by-arguments:
          72 x access:
            REC_gASI_bPowerOnReset_Val: accessed-variable=gASI_bPowerOnReset.Val
            REC_gCAN_bBCS_VehSpdVD_Val: accessed-variable=gCAN_bBCS_VehSpdVD.Val
            REC_gCAN_bLCK_FillerCapLock_Alock_Val: accessed-variable=gCAN_bLCK_FillerCapLock_Alock.Val
            REC_gCAN_bLCK_FillerCapLock_Block_Val: accessed-variable=gCAN_bLCK_FillerCapLock_Block.Val
            REC_gCAN_bLCK_PowerFillerCap_Val: accessed-variable=gCAN_bLCK_PowerFillerCap.Val
            REC_gCAN_bLCK_RearLeftChildSaftyLock_Val: accessed-variable=gCAN_bLCK_RearLeftChildSaftyLock.Val
            REC_gCAN_bLCK_RearLeftDoorLock_Val: accessed-variable=gCAN_bLCK_RearLeftDoorLock.Val
            REC_gCAN_bLCK_RearLeftPowerDoor_Val: accessed-variable=gCAN_bLCK_RearLeftPowerDoor.Val
            REC_gCAN_bLCK_RearRightChildSaftyLock_Val: accessed-variable=gCAN_bLCK_RearRightChildSaftyLock.Val
            REC_gCAN_bLCK_RearRightDoorLock_Val: accessed-variable=gCAN_bLCK_RearRightDoorLock.Val
            REC_gCAN_bLCK_RearRightPowerDoor_Val: accessed-variable=gCAN_bLCK_RearRightPowerDoor.Val
            REC_gCAN_bLCK_TrunkLock_Val: accessed-variable=gCAN_bLCK_TrunkLock.Val
            REC_gCAN_u16BCS_VehSpd_Val: accessed-variable=gCAN_u16BCS_VehSpd.Val
            REC_gCAN_u8LCK_FillerCapCommandActionType_Val: accessed-variable=gCAN_u8LCK_FillerCapCommandActionType.Val
            REC_gCAN_u8LCK_LockCommandActionType_Val: accessed-variable=gCAN_u8LCK_LockCommandActionType.Val
            REC_gCAN_u8LCK_PowerDoorCommandActionType_Val: accessed-variable=gCAN_u8LCK_PowerDoorCommandActionType.Val
            REC_gCAN_u8SRS_CrashOutputSt_Val: accessed-variable=gCAN_u8SRS_CrashOutputSt.Val
            REC_gCAN_u8UMM_UsageModeSt_Val: accessed-variable=gCAN_u8UMM_UsageModeSt.Val
            REC_gCAN_u8VCU_CrntGearLvl_A02_Val: accessed-variable=gCAN_u8VCU_CrntGearLvl_A02.Val
            REC_gCAN_u8VCU_CrntGearLvl_A09_Val: accessed-variable=gCAN_u8VCU_CrntGearLvl_A09.Val
            REC_gCFG_bLCK_PowerFillerCapCfg_Val: accessed-variable=gCFG_bLCK_PowerFillerCapCfg.Val
            REC_gCrash_bRLCrashUnlockSwt_Val: accessed-variable=gCrash_bRLCrashUnlockSwt.Val
            REC_gCrash_bRRCrashUnlockSwt_Val: accessed-variable=gCrash_bRRCrashUnlockSwt.Val
            REC_gDoor_bChrgCapAjarSt_Val: accessed-variable=gDoor_bChrgCapAjarSt.Val
            REC_gDoor_bFuelFlapAjarSt_Val: accessed-variable=gDoor_bFuelFlapAjarSt.Val
            REC_gDoor_bRLDoorAjarSt_Val: accessed-variable=gDoor_bRLDoorAjarSt.Val
            REC_gDoor_bRRDoorAjarSt_Val: accessed-variable=gDoor_bRRDoorAjarSt.Val
            REC_gDoor_bTrunkAjarSt_Val: accessed-variable=gDoor_bTrunkAjarSt.Val
            REC_gLock_bChrgCapSwt_Val: accessed-variable=gLock_bChrgCapSwt.Val
            REC_gLock_bRLChildLockFbSt_Val: accessed-variable=gLock_bRLChildLockFbSt.Val
            REC_gLock_bRLChildLockMotorTrigUds_Val: accessed-variable=gLock_bRLChildLockMotorTrigUds.Val
            REC_gLock_bRLDoorLockFbSt_Val: accessed-variable=gLock_bRLDoorLockFbSt.Val
            REC_gLock_bRLDoorLockMotorTrigUds_Val: accessed-variable=gLock_bRLDoorLockMotorTrigUds.Val
            REC_gLock_bRLPwrDoorTrigUds_Val: accessed-variable=gLock_bRLPwrDoorTrigUds.Val
            REC_gLock_bRRChildLockFbSt_Val: accessed-variable=gLock_bRRChildLockFbSt.Val
            REC_gLock_bRRChildLockMotorTrigUds_Val: accessed-variable=gLock_bRRChildLockMotorTrigUds.Val
            REC_gLock_bRRDoorLockFbSt_Val: accessed-variable=gLock_bRRDoorLockFbSt.Val
            REC_gLock_bRRDoorLockMotorTrigUds_Val: accessed-variable=gLock_bRRDoorLockMotorTrigUds.Val
            REC_gLock_bRRPwrDoorTrigUds_Val: accessed-variable=gLock_bRRPwrDoorTrigUds.Val
            REC_gLock_u16ChrgCapPosVolt_Val: accessed-variable=gLock_u16ChrgCapPosVolt.Val
            REC_gLock_u8BootLockMotorPs_Val: accessed-variable=gLock_u8BootLockMotorPs.Val
            REC_gLock_u8ChrgCapLockMotorPs_Val: accessed-variable=gLock_u8ChrgCapLockMotorPs.Val
            REC_gLock_u8DiagEnbCnd_Val: accessed-variable=gLock_u8DiagEnbCnd.Val
            REC_gLock_u8OilTankLockMotorPs_Val: accessed-variable=gLock_u8OilTankLockMotorPs.Val
            REC_gLock_u8RLChildLockMotorPs_Val: accessed-variable=gLock_u8RLChildLockMotorPs.Val
            REC_gLock_u8RLChildLockMotorUds_Val: accessed-variable=gLock_u8RLChildLockMotorUds.Val
            REC_gLock_u8RLDoorLockMotorPs_Val: accessed-variable=gLock_u8RLDoorLockMotorPs.Val
            REC_gLock_u8RLDoorLockMotorUds_Val: accessed-variable=gLock_u8RLDoorLockMotorUds.Val
            REC_gLock_u8RLPwrDoorUds_Val: accessed-variable=gLock_u8RLPwrDoorUds.Val
            REC_gLock_u8RLPwrRelsMotorPs_Val: accessed-variable=gLock_u8RLPwrRelsMotorPs.Val
            REC_gLock_u8RRChildLockMotorPs_Val: accessed-variable=gLock_u8RRChildLockMotorPs.Val
            REC_gLock_u8RRChildLockMotorUds_Val: accessed-variable=gLock_u8RRChildLockMotorUds.Val
            REC_gLock_u8RRDoorLockMotorPs_Val: accessed-variable=gLock_u8RRDoorLockMotorPs.Val
            REC_gLock_u8RRDoorLockMotorUds_Val: accessed-variable=gLock_u8RRDoorLockMotorUds.Val
            REC_gLock_u8RRPwrDoorUds_Val: accessed-variable=gLock_u8RRPwrDoorUds.Val
            REC_gLock_u8RRPwrRelsMotorPs_Val: accessed-variable=gLock_u8RRPwrRelsMotorPs.Val
            REC_gPRM_u8PowerDoorCfg_Val: accessed-variable=gPRM_u8PowerDoorCfg.Val
            REC_gPRM_u8tAjarKeepAwakeCfg_Val: accessed-variable=gPRM_u8tAjarKeepAwakeCfg.Val
            REC_gPRM_u8tDoorsLockUnlockCfg_Val: accessed-variable=gPRM_u8tDoorsLockUnlockCfg.Val
            REC_gPRM_u8tFillerCapLockUnlockCfg_Val: accessed-variable=gPRM_u8tFillerCapLockUnlockCfg.Val
            REC_gPRM_u8tIntervalEmgcUnlockCfg_Val: accessed-variable=gPRM_u8tIntervalEmgcUnlockCfg.Val
            REC_gPRM_u8tIntervalReverseUnlockCfg_Val: accessed-variable=gPRM_u8tIntervalReverseUnlockCfg.Val
            REC_gPRM_u8tPowerCinchCfg_Val: accessed-variable=gPRM_u8tPowerCinchCfg.Val
            REC_gPRM_u8tPowerReleaseCfg_Val: accessed-variable=gPRM_u8tPowerReleaseCfg.Val
            REC_gPRM_u8tPowerReleaseTimeOutCfg_Val: accessed-variable=gPRM_u8tPowerReleaseTimeOutCfg.Val
            REC_gPRM_u8tTrunkUnlockCfg_Val: accessed-variable=gPRM_u8tTrunkUnlockCfg.Val
            REC_gPRM_u8VehicleTypeCfg_Val: accessed-variable=gPRM_u8VehicleTypeCfg.Val
            REC_gSuctnDoor_bRLInPwrRelsSwt_Val: accessed-variable=gSuctnDoor_bRLInPwrRelsSwt.Val
            REC_gSuctnDoor_bRLSecLockFbSt_Val: accessed-variable=gSuctnDoor_bRLSecLockFbSt.Val
            REC_gSuctnDoor_bRRInPwrRlesSwt_Val: accessed-variable=gSuctnDoor_bRRInPwrRlesSwt.Val
            REC_gSuctnDoor_bRRSecLockFbSt_Val: accessed-variable=gSuctnDoor_bRRSecLockFbSt.Val
            REC_gVRM_u16BatteryVolt_mv_Val: accessed-variable=gVRM_u16BatteryVolt_mv.Val
        data-send-points:
          92 x access:
            SEND_gLOC_bLCK_ExterSwOpenFillerCapReq_Val: accessed-variable=gLOC_bLCK_ExterSwOpenFillerCapReq.Val
            SEND_gLOC_bLCK_RearLeftChildSaftyLockSt_Val: accessed-variable=gLOC_bLCK_RearLeftChildSaftyLockSt.Val
            SEND_gLOC_bLCK_RearLeftDoorAjarSt_Val: accessed-variable=gLOC_bLCK_RearLeftDoorAjarSt.Val
            SEND_gLOC_bLCK_RearLeftDoorLockSt_Val: accessed-variable=gLOC_bLCK_RearLeftDoorLockSt.Val
            SEND_gLOC_bLCK_RearLeftDoorOpenSt_Val: accessed-variable=gLOC_bLCK_RearLeftDoorOpenSt.Val
            SEND_gLOC_bLCK_RearRightChildSaftyLockSt_Val: accessed-variable=gLOC_bLCK_RearRightChildSaftyLockSt.Val
            SEND_gLOC_bLCK_RearRightDoorAjarSt_Val: accessed-variable=gLOC_bLCK_RearRightDoorAjarSt.Val
            SEND_gLOC_bLCK_RearRightDoorLockSt_Val: accessed-variable=gLOC_bLCK_RearRightDoorLockSt.Val
            SEND_gLOC_bLCK_RearRightDoorOpenSt_Val: accessed-variable=gLOC_bLCK_RearRightDoorOpenSt.Val
            SEND_gLOC_bLCK_TrunkAjarSt_Val: accessed-variable=gLOC_bLCK_TrunkAjarSt.Val
            SEND_gLOC_bUINM_RearLeftPowerReleaseReq_Val: accessed-variable=gLOC_bUINM_RearLeftPowerReleaseReq.Val
            SEND_gLOC_bUINM_RearRightPowerReleaseReq_Val: accessed-variable=gLOC_bUINM_RearRightPowerReleaseReq.Val
            SEND_gLOC_u32AllowSleep_Local_Val: accessed-variable=gLOC_u32AllowSleep_Local.Val
            SEND_gLOC_u32AllowSleep_NW_Val: accessed-variable=gLOC_u32AllowSleep_NW.Val
            SEND_gLOC_u8LCK_FillerCapAction_Val: accessed-variable=gLOC_u8LCK_FillerCapAction.Val
            SEND_gLOC_u8LCK_FillerCapAngle_Val: accessed-variable=gLOC_u8LCK_FillerCapAngle.Val
            SEND_gLOC_u8LCK_FillerCapLock_AAction_Val: accessed-variable=gLOC_u8LCK_FillerCapLock_AAction.Val
            SEND_gLOC_u8LCK_FillerCapLock_BAction_Val: accessed-variable=gLOC_u8LCK_FillerCapLock_BAction.Val
            SEND_gLOC_u8LCK_RearLeftChildSaftyLockAction_Val: accessed-variable=gLOC_u8LCK_RearLeftChildSaftyLockAction.Val
            SEND_gLOC_u8LCK_RearLeftDoorLockAction_Val: accessed-variable=gLOC_u8LCK_RearLeftDoorLockAction.Val
            SEND_gLOC_u8LCK_RearLeftPowerDoorAction_Val: accessed-variable=gLOC_u8LCK_RearLeftPowerDoorAction.Val
            SEND_gLOC_u8LCK_RearRightChildSaftyLockAction_Val: accessed-variable=gLOC_u8LCK_RearRightChildSaftyLockAction.Val
            SEND_gLOC_u8LCK_RearRightDoorLockAction_Val: accessed-variable=gLOC_u8LCK_RearRightDoorLockAction.Val
            SEND_gLOC_u8LCK_RearRightPowerDoorAction_Val: accessed-variable=gLOC_u8LCK_RearRightPowerDoorAction.Val
            SEND_gLOC_u8LCK_TrunkLockAction_Val: accessed-variable=gLOC_u8LCK_TrunkLockAction.Val
            SEND_gLock_bLCK_FillerCapASt_Val: accessed-variable=gLock_bLCK_FillerCapASt.Val
            SEND_gLock_bLCK_FillerCapBSt_Val: accessed-variable=gLock_bLCK_FillerCapBSt.Val
            SEND_gLock_bLCK_RearLeftPowerReleaseFailedRemind_Val: accessed-variable=gLock_bLCK_RearLeftPowerReleaseFailedRemind.Val
            SEND_gLock_bLCK_RearRightPowerReleaseFailedRemind_Val: accessed-variable=gLock_bLCK_RearRightPowerReleaseFailedRemind.Val
            SEND_gLock_bUINM_RearLeftPowerReleaseFaultSt_Val: accessed-variable=gLock_bUINM_RearLeftPowerReleaseFaultSt.Val
            SEND_gLock_bUINM_RearRightPowerReleaseFaultSt_Val: accessed-variable=gLock_bUINM_RearRightPowerReleaseFaultSt.Val
            SEND_gLockCtrl_bChrgCapSwtDTCFlag_Val: accessed-variable=gLockCtrl_bChrgCapSwtDTCFlag.Val
            SEND_gLockCtrl_bFillerCapAMotorMoveFlag_Val: accessed-variable=gLockCtrl_bFillerCapAMotorMoveFlag.Val
            SEND_gLockCtrl_bFillerCapARelockFlag_Val: accessed-variable=gLockCtrl_bFillerCapARelockFlag.Val
            SEND_gLockCtrl_bFillerCapAReUnlockFlag_Val: accessed-variable=gLockCtrl_bFillerCapAReUnlockFlag.Val
            SEND_gLockCtrl_bFillerCapBMotorMoveFlag_Val: accessed-variable=gLockCtrl_bFillerCapBMotorMoveFlag.Val
            SEND_gLockCtrl_bFillerCapBRelockFlag_Val: accessed-variable=gLockCtrl_bFillerCapBRelockFlag.Val
            SEND_gLockCtrl_bFillerCapBReUnlockFlag_Val: accessed-variable=gLockCtrl_bFillerCapBReUnlockFlag.Val
            SEND_gLockCtrl_bRLCSLDoorMotorMoveFlag_Val: accessed-variable=gLockCtrl_bRLCSLDoorMotorMoveFlag.Val
            SEND_gLockCtrl_bRLCSLLockMotorReEmergencyunlockflag_Val: accessed-variable=gLockCtrl_bRLCSLLockMotorReEmergencyunlockflag.Val
            SEND_gLockCtrl_bRLCSLLockMotorRelockflag_Val: accessed-variable=gLockCtrl_bRLCSLLockMotorRelockflag.Val
            SEND_gLockCtrl_bRLCSLLockMotorReReverseunlockflag_Val: accessed-variable=gLockCtrl_bRLCSLLockMotorReReverseunlockflag.Val
            SEND_gLockCtrl_bRLCSLLockMotorReunlockflag_Val: accessed-variable=gLockCtrl_bRLCSLLockMotorReunlockflag.Val
            SEND_gLockCtrl_bRLDoorMotorMoveFlag_Val: accessed-variable=gLockCtrl_bRLDoorMotorMoveFlag.Val
            SEND_gLockCtrl_bRLLockMotorReEmergencyunlockflag_Val: accessed-variable=gLockCtrl_bRLLockMotorReEmergencyunlockflag.Val
            SEND_gLockCtrl_bRLLockMotorRelockflag_Val: accessed-variable=gLockCtrl_bRLLockMotorRelockflag.Val
            SEND_gLockCtrl_bRLLockMotorReReverseunlockflag_Val: accessed-variable=gLockCtrl_bRLLockMotorReReverseunlockflag.Val
            SEND_gLockCtrl_bRLLockMotorReunlockflag_Val: accessed-variable=gLockCtrl_bRLLockMotorReunlockflag.Val
            SEND_gLockCtrl_bRLPowerDoorRelsMotorMoveFlag_Val: accessed-variable=gLockCtrl_bRLPowerDoorRelsMotorMoveFlag.Val
            SEND_gLockCtrl_bRLPowerDoorReReleaseflag_Val: accessed-variable=gLockCtrl_bRLPowerDoorReReleaseflag.Val
            SEND_gLockCtrl_bRLPowerReleaseSwDTCFlag_Val: accessed-variable=gLockCtrl_bRLPowerReleaseSwDTCFlag.Val
            SEND_gLockCtrl_bRRCSLDoorMotorMoveFlag_Val: accessed-variable=gLockCtrl_bRRCSLDoorMotorMoveFlag.Val
            SEND_gLockCtrl_bRRCSLLockMotorReEmergencyunlockflag_Val: accessed-variable=gLockCtrl_bRRCSLLockMotorReEmergencyunlockflag.Val
            SEND_gLockCtrl_bRRCSLLockMotorRelockflag_Val: accessed-variable=gLockCtrl_bRRCSLLockMotorRelockflag.Val
            SEND_gLockCtrl_bRRCSLLockMotorReReverseunlockflag_Val: accessed-variable=gLockCtrl_bRRCSLLockMotorReReverseunlockflag.Val
            SEND_gLockCtrl_bRRCSLLockMotorReunlockflag_Val: accessed-variable=gLockCtrl_bRRCSLLockMotorReunlockflag.Val
            SEND_gLockCtrl_bRRDoorMotorMoveFlag_Val: accessed-variable=gLockCtrl_bRRDoorMotorMoveFlag.Val
            SEND_gLockCtrl_bRRLockMotorReEmergencyunlockflag_Val: accessed-variable=gLockCtrl_bRRLockMotorReEmergencyunlockflag.Val
            SEND_gLockCtrl_bRRLockMotorRelockflag_Val: accessed-variable=gLockCtrl_bRRLockMotorRelockflag.Val
            SEND_gLockCtrl_bRRLockMotorReReverseunlockflag_Val: accessed-variable=gLockCtrl_bRRLockMotorReReverseunlockflag.Val
            SEND_gLockCtrl_bRRLockMotorReunlockflag_Val: accessed-variable=gLockCtrl_bRRLockMotorReunlockflag.Val
            SEND_gLockCtrl_bRRPowerDoorRelsMotorMoveFlag_Val: accessed-variable=gLockCtrl_bRRPowerDoorRelsMotorMoveFlag.Val
            SEND_gLockCtrl_bRRPowerDoorReReleaseflag_Val: accessed-variable=gLockCtrl_bRRPowerDoorReReleaseflag.Val
            SEND_gLockCtrl_bRRPowerReleaseSwDTCFlag_Val: accessed-variable=gLockCtrl_bRRPowerReleaseSwDTCFlag.Val
            SEND_gLockCtrl_bTrunkMotorMoveFlag_Val: accessed-variable=gLockCtrl_bTrunkMotorMoveFlag.Val
            SEND_gLockCtrl_bTrunkReUnlockFlag_Val: accessed-variable=gLockCtrl_bTrunkReUnlockFlag.Val
            SEND_gLockCtrl_u8BootLockMotorOutput_Val: accessed-variable=gLockCtrl_u8BootLockMotorOutput.Val
            SEND_gLockCtrl_u8ChrgCapLockMotorOutput_Val: accessed-variable=gLockCtrl_u8ChrgCapLockMotorOutput.Val
            SEND_gLockCtrl_u8FillerCapAMotorCmd_Val: accessed-variable=gLockCtrl_u8FillerCapAMotorCmd.Val
            SEND_gLockCtrl_u8FillerCapBMotorCmd_Val: accessed-variable=gLockCtrl_u8FillerCapBMotorCmd.Val
            SEND_gLockCtrl_u8FillerCapLockReqA_Val: accessed-variable=gLockCtrl_u8FillerCapLockReqA.Val
            SEND_gLockCtrl_u8FillerCapLockReqB_Val: accessed-variable=gLockCtrl_u8FillerCapLockReqB.Val
            SEND_gLockCtrl_u8OilTankLockMotorOutput_Val: accessed-variable=gLockCtrl_u8OilTankLockMotorOutput.Val
            SEND_gLockCtrl_u8RLChildLockMotorOutput_Val: accessed-variable=gLockCtrl_u8RLChildLockMotorOutput.Val
            SEND_gLockCtrl_u8RLCSLLockMotorCmd_Val: accessed-variable=gLockCtrl_u8RLCSLLockMotorCmd.Val
            SEND_gLockCtrl_u8RLDoorElecRelMotorOutput_Val: accessed-variable=gLockCtrl_u8RLDoorElecRelMotorOutput.Val
            SEND_gLockCtrl_u8RLDoorElecRelPWMMotorOutput_Val: accessed-variable=gLockCtrl_u8RLDoorElecRelPWMMotorOutput.Val
            SEND_gLockCtrl_u8RLDoorLockMotorOutput_Val: accessed-variable=gLockCtrl_u8RLDoorLockMotorOutput.Val
            SEND_gLockCtrl_u8RLLockMotorCmd_Val: accessed-variable=gLockCtrl_u8RLLockMotorCmd.Val
            SEND_gLockCtrl_u8RLPowerDoorRelCmd_Val: accessed-variable=gLockCtrl_u8RLPowerDoorRelCmd.Val
            SEND_gLockCtrl_u8RLPowerDoorRelDoneFlag_Val: accessed-variable=gLockCtrl_u8RLPowerDoorRelDoneFlag.Val
            SEND_gLockCtrl_u8RLPowerDoorReq_Val: accessed-variable=gLockCtrl_u8RLPowerDoorReq.Val
            SEND_gLockCtrl_u8RRChildLockMotorOutput_Val: accessed-variable=gLockCtrl_u8RRChildLockMotorOutput.Val
            SEND_gLockCtrl_u8RRCSLLockMotorCmd_Val: accessed-variable=gLockCtrl_u8RRCSLLockMotorCmd.Val
            SEND_gLockCtrl_u8RRDoorElecRelMotorOutput_Val: accessed-variable=gLockCtrl_u8RRDoorElecRelMotorOutput.Val
            SEND_gLockCtrl_u8RRDoorElecRelPWMMotorOutput_Val: accessed-variable=gLockCtrl_u8RRDoorElecRelPWMMotorOutput.Val
            SEND_gLockCtrl_u8RRDoorLockMotorOutput_Val: accessed-variable=gLockCtrl_u8RRDoorLockMotorOutput.Val
            SEND_gLockCtrl_u8RRLockMotorCmd_Val: accessed-variable=gLockCtrl_u8RRLockMotorCmd.Val
            SEND_gLockCtrl_u8RRPowerDoorRelCmd_Val: accessed-variable=gLockCtrl_u8RRPowerDoorRelCmd.Val
            SEND_gLockCtrl_u8RRPowerDoorRelDoneFlag_Val: accessed-variable=gLockCtrl_u8RRPowerDoorRelDoneFlag.Val
            SEND_gLockCtrl_u8RRPowerDoorReq_Val: accessed-variable=gLockCtrl_u8RRPowerDoorReq.Val
            SEND_gLockCtrl_u8TrunkDoorUnlockReq_Val: accessed-variable=gLockCtrl_u8TrunkDoorUnlockReq.Val
        10 x parameter access:
          PA_Cal_bPowerFillerOverride: accessed-parameter=Cal_bPowerFillerOverride
          PA_Cal_FillerCapResetVolt: accessed-parameter=Cal_FillerCapResetVolt
          PA_Cal_MaxOperationTime: accessed-parameter=Cal_MaxOperationTime
          PA_Cal_MaxStallPrm: accessed-parameter=Cal_MaxStallPrm
          PA_Cal_MaxStallTime: accessed-parameter=Cal_MaxStallTime
          PA_Cal_MaxStallVolt: accessed-parameter=Cal_MaxStallVolt
          PA_Cal_MinStallVolt: accessed-parameter=Cal_MinStallVolt
          PA_Cal_NoActionTime: accessed-parameter=Cal_NoActionTime
          PA_Cal_ReactWaitTime: accessed-parameter=Cal_ReactWaitTime
          PA_Cal_UinitDelay: accessed-parameter=Cal_UinitDelay
        12 x sync call, all with timeout=1E-06:
          SC_DTC_RLDoorAjarOL_GetEventFailed: operation=DTC_RLDoorAjarOL.GetEventFailed
          SC_DTC_RLDoorAjarOL_ResetEventDebounceStatus: operation=DTC_RLDoorAjarOL.ResetEventDebounceStatus
          SC_DTC_RLDoorAjarOL_SetEventStatus: operation=DTC_RLDoorAjarOL.SetEventStatus
          SC_DTC_RLPwrRelsSwtStick_GetEventFailed: operation=DTC_RLPwrRelsSwtStick.GetEventFailed
          SC_DTC_RLPwrRelsSwtStick_ResetEventDebounceStatus: operation=DTC_RLPwrRelsSwtStick.ResetEventDebounceStatus
          SC_DTC_RLPwrRelsSwtStick_SetEventStatus: operation=DTC_RLPwrRelsSwtStick.SetEventStatus
          SC_DTC_RRDoorAjarOL_GetEventFailed: operation=DTC_RRDoorAjarOL.GetEventFailed
          SC_DTC_RRDoorAjarOL_ResetEventDebounceStatus: operation=DTC_RRDoorAjarOL.ResetEventDebounceStatus
          SC_DTC_RRDoorAjarOL_SetEventStatus: operation=DTC_RRDoorAjarOL.SetEventStatus
          SC_DTC_RRPwrRelsSwtStick_GetEventFailed: operation=DTC_RRPwrRelsSwtStick.GetEventFailed
          SC_DTC_RRPwrRelsSwtStick_ResetEventDebounceStatus: operation=DTC_RRPwrRelsSwtStick.ResetEventDebounceStatus
          SC_DTC_RRPwrRelsSwtStick_SetEventStatus: operation=DTC_RRPwrRelsSwtStick.SetEventStatus
      runnable Lock_Ctrl_Runnable_Init
        10 x parameter access:
          PA_Cal_bPowerFillerOverride: accessed-parameter=Cal_bPowerFillerOverride
          PA_Cal_FillerCapResetVolt: accessed-parameter=Cal_FillerCapResetVolt
          PA_Cal_MaxOperationTime: accessed-parameter=Cal_MaxOperationTime
          PA_Cal_MaxStallPrm: accessed-parameter=Cal_MaxStallPrm
          PA_Cal_MaxStallTime: accessed-parameter=Cal_MaxStallTime
          PA_Cal_MaxStallVolt: accessed-parameter=Cal_MaxStallVolt
          PA_Cal_MinStallVolt: accessed-parameter=Cal_MinStallVolt
          PA_Cal_NoActionTime: accessed-parameter=Cal_NoActionTime
          PA_Cal_ReactWaitTime: accessed-parameter=Cal_ReactWaitTime
          PA_Cal_UinitDelay: accessed-parameter=Cal_UinitDelay
      shared-parameters:
        10 x parameter data prototype, all with sw-calibration-access=READ-WRITE:
          Cal_bPowerFillerOverride: type=ImplementationDataTypes/uint16, init-value=constant-reference={short-label=Cal_bPowerFillerOverride, constant=Cal_bPowerFillerOverride}
          Cal_FillerCapResetVolt: type=Float, init-value=constant-reference={short-label=Cal_FillerCapResetVolt, constant=Cal_FillerCapResetVolt}
          Cal_MaxOperationTime: type=ImplementationDataTypes/uint16, init-value=constant-reference={short-label=Cal_MaxOperationTime, constant=Cal_MaxOperationTime}
          Cal_MaxStallPrm: type=ImplementationDataTypes/uint16, init-value=constant-reference={short-label=Cal_MaxStallPrm, constant=Cal_MaxStallPrm}
          Cal_MaxStallTime: type=ImplementationDataTypes/uint16, init-value=constant-reference={short-label=Cal_MaxStallTime, constant=Cal_MaxStallTime}
          Cal_MaxStallVolt: type=Float, init-value=constant-reference={short-label=Cal_MaxStallVolt, constant=Cal_MaxStallVolt}
          Cal_MinStallVolt: type=Float, init-value=constant-reference={short-label=Cal_MinStallVolt, constant=Cal_MinStallVolt}
          Cal_NoActionTime: type=ImplementationDataTypes/uint16
          Cal_ReactWaitTime: type=ImplementationDataTypes/uint16, init-value=constant-reference={short-label=Cal_ReactWaitTime, constant=Cal_ReactWaitTime}
          Cal_UinitDelay: type=ImplementationDataTypes/uint16, init-value=constant-reference={short-label=Cal_UinitDelay, constant=Cal_UinitDelay}
  swc implementation Lock_Ctrl_Implementation: behavior=Lock_Ctrl_InternalBehavior
    code-descriptors:
      code Default: artifact-descriptors=autosar-engineering-object={short-label=Default, category=SWSRC}
package /UAES/ASW/Units
  unit NoUnit: factor-si-to-unit=1, offset-si-to-unit=0
